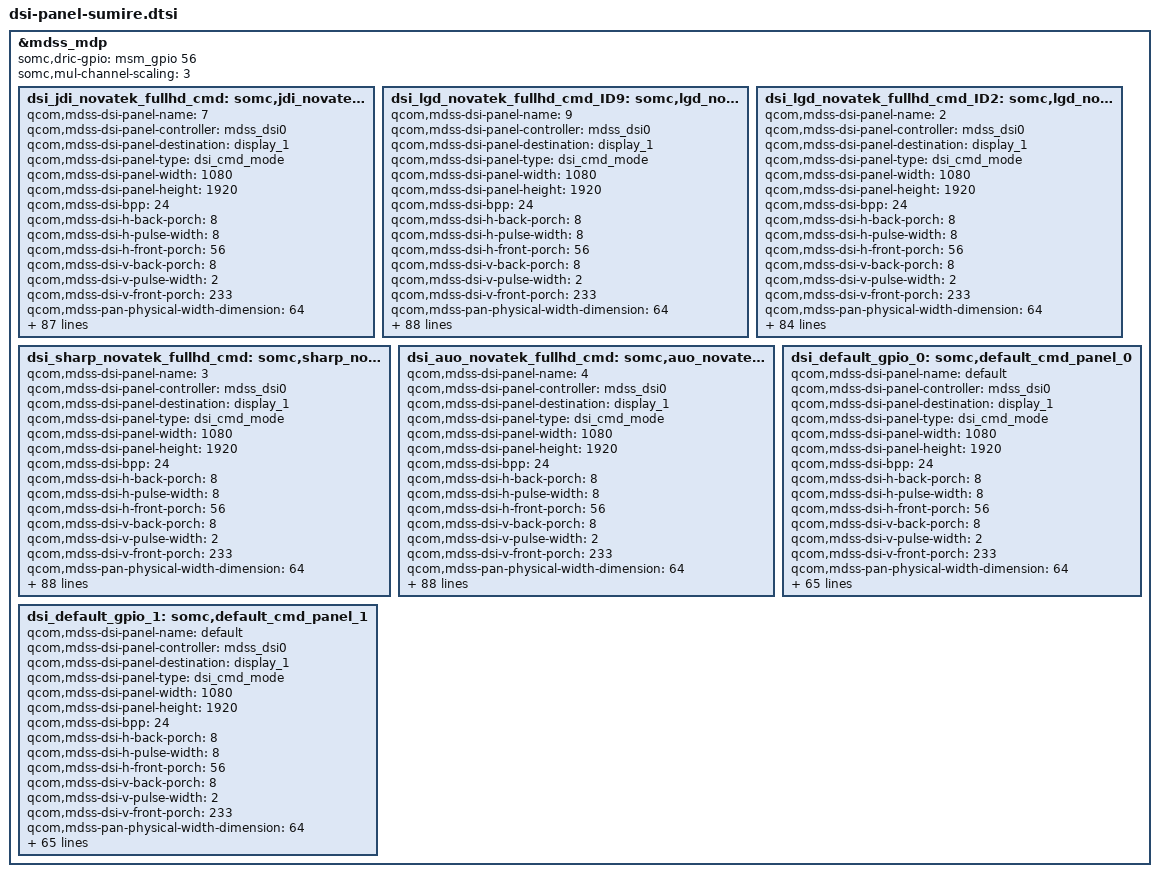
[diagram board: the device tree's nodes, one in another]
/* Copyright (c) 2013-2015, The Linux Foundation. All rights reserved.
 *
 * This program is free software; you can redistribute it and/or modify
 * it under the terms of the GNU General Public License version 2 and
 * only version 2 as published by the Free Software Foundation.
 *
 * This program is distributed in the hope that it will be useful,
 * but WITHOUT ANY WARRANTY; without even the implied warranty of
 * MERCHANTABILITY or FITNESS FOR A PARTICULAR PURPOSE.  See the
 * GNU General Public License for more details.
 */
/*
 * Copyright (C) 2015 Sony Mobile Communications Inc.
 *
 * This program is free software; you can redistribute it and/or modify
 * it under the terms of the GNU General Public License version 2, as
 * published by the Free Software Foundation.
 */

&mdss_mdp {
	somc,dric-gpio = <&msm_gpio 56 0>;
	somc,mul-channel-scaling = <3>;

	dsi_jdi_novatek_fullhd_cmd: somc,jdi_novatek_fullhd_cmd_panel {
		qcom,mdss-dsi-panel-name = "7";
		qcom,mdss-dsi-panel-controller = <&mdss_dsi0>;
		qcom,mdss-dsi-panel-destination = "display_1";
		qcom,mdss-dsi-panel-type = "dsi_cmd_mode";
		qcom,mdss-dsi-panel-width = <1080>;
		qcom,mdss-dsi-panel-height = <1920>;
		qcom,mdss-dsi-bpp = <24>;
		qcom,mdss-dsi-h-back-porch = <8>;
		qcom,mdss-dsi-h-pulse-width = <8>;
		qcom,mdss-dsi-h-front-porch = <56>;
		qcom,mdss-dsi-v-back-porch = <8>;
		qcom,mdss-dsi-v-pulse-width = <2>;
		qcom,mdss-dsi-v-front-porch = <233>;
		qcom,mdss-pan-physical-width-dimension = <64>;
		qcom,mdss-pan-physical-height-dimension = <114>;
		qcom,mdss-dsi-panel-framerate = <60>;
		qcom,mdss-dsi-virtual-channel-id = <0>;
		qcom,mdss-dsi-stream = <0>;
		qcom,mdss-dsi-h-sync-skew = <0>;
		qcom,mdss-dsi-h-left-border = <0>;
		qcom,mdss-dsi-h-right-border = <0>;
		qcom,mdss-dsi-v-top-border = <0>;
		qcom,mdss-dsi-v-bottom-border = <0>;
		qcom,mdss-dsi-underflow-color = <0x0>;
		qcom,mdss-dsi-border-color = <0>;
		qcom,mdss-dsi-h-sync-pulse = <1>;
		qcom,mdss-dsi-traffic-mode = "non_burst_sync_event";
		qcom,mdss-dsi-bllp-eof-power-mode;
		qcom,mdss-dsi-bllp-power-mode;
		qcom,mdss-dsi-dma-trigger = "trigger_sw";
		qcom,mdss-dsi-mdp-trigger = "none";
		somc,mdss-dsi-init-command = [23 01 00 00 00 00 02 FF 10
				05 01 00 00 14 00 01 01
				23 01 00 00 00 00 02 FB 01
				15 01 00 00 00 00 02 BB 10
				15 01 00 00 00 00 02 35 00
				39 01 00 00 00 00 03 44 03 00
				39 01 00 00 00 00 04 3B 03 08 08
				23 01 00 00 00 00 02 FF E0
				23 01 00 00 00 00 02 B5 86
				23 01 00 00 00 00 02 B6 77
				23 01 00 00 00 00 02 B8 AD
				23 01 00 00 00 00 02 FB 01
				23 01 00 00 00 00 02 FF 24
				23 01 00 00 00 00 02 FB 01
				23 01 00 00 00 00 02 92 8E
				23 01 00 00 00 00 02 FF 10
				23 01 00 00 01 00 02 FB 01
				05 01 00 00 00 00 01 29];
		qcom,mdss-dsi-on-command = [05 01 00 00 0A 00 01 11];
		qcom,mdss-dsi-off-command = [05 01 00 00 14 00 01 28
				05 01 00 00 50 00 01 10];
		qcom,mdss-dsi-on-command-state = "dsi_lp_mode";
		qcom,mdss-dsi-off-command-state = "dsi_hs_mode";
		qcom,mdss-dsi-te-pin-select = <1>;
		qcom,mdss-dsi-wr-mem-start = <0x2c>;
		qcom,mdss-dsi-wr-mem-continue = <0x3c>;
		qcom,mdss-dsi-te-dcs-command = <1>;
		qcom,mdss-dsi-te-check-enable;
		qcom,mdss-dsi-te-using-te-pin;
		qcom,mdss-dsi-lane-0-state;
		qcom,mdss-dsi-lane-1-state;
		qcom,mdss-dsi-lane-2-state;
		qcom,mdss-dsi-lane-3-state;
		qcom,mdss-dsi-panel-timings = [E6 38 26 00 68 66 32 3C 2C 03 04 00];
		qcom,mdss-dsi-t-clk-post = <0x21>;
		qcom,mdss-dsi-t-clk-pre = <0x2B>;
		qcom,mdss-dsi-tx-eot-append;
		qcom,mdss-dsi-lp11-init;
		qcom,mdss-dsi-bl-min-level = <1>;
		qcom,mdss-dsi-bl-max-level = <4095>;
		qcom,mdss-brightness-max-level = <4095>;
		qcom,mdss-dsi-bl-pmic-control-type = "bl_ctrl_wled";
		qcom,qpnp-lab-limit-maximum-current = <200>;
		qcom,qpnp-ibb-limit-maximum-current = <800>;

		somc,mdss-dsi-disp-on-in-hs = <0>;
		somc,mdss-dsi-wait-time-before-on-cmd = <0>;
		somc,platform-regulator-settings = [03 03 03 00 20 00 01];
		somc,mdss-dsi-lane-config = [02 00 EF 00 20 00 00 01 FF
				02 00 EF 00 40 00 00 01 FF
				02 00 EF 40 20 00 00 01 FF
				02 00 EF 40 00 00 00 01 FF
				00 00 45 80 00 00 00 01 97];
		somc,pw-on-rst-seq = <0 20>, <1 15>;
		somc,disp-en-off-post = <70>;
		somc,pw-off-rst-seq = <0 0>;
		somc,pw-down-period = <100>;
		somc,lab-output-voltage = <5400000>;
		somc,ibb-output-voltage = <5400000>;
		somc,lcd-id = <1>;
		somc,lcd-id-adc = <353000 414000>;
		somc,mdss-dsi-master;

		somc,change-fps-enable;
		somc,change-fps-command = [15 01 00 00 00 00 02 FF 24
				15 01 00 00 00 00 02 92 8E
				15 01 00 00 00 00 02 FF 10
				39 01 00 00 00 00 03 44 03 00];
		somc,display-clock = <16660000>;
		somc,driver-ic-vbp = <8>;
		somc,driver-ic-vfp = <8>;
		somc,change-fps-rtn-adj;
		somc,change-fps-rtn-pos = <1 1>;
		somc,fps-threshold = <47400>;
		somc,te-c-mode-60fps = <0x03 0x00>;
		somc,te-c-mode-45fps = <0x04 0xFF>;
		somc,te-c-mode-pos = <3 1>;

		somc,mdss-dsi-lock-command = [15 01 00 00 00 00 02 FF 10
				15 01 00 00 00 00 02 FB 01
				15 01 00 00 00 00 02 F0 55
				15 01 00 00 00 00 02 F1 AA
				15 01 00 00 01 00 02 F2 66];

		somc,mdss-dsi-unlock-command = [15 01 00 00 00 00 02 FF 10
				15 01 00 00 00 00 02 FB 01
				15 01 00 00 00 00 02 F0 AA
				15 01 00 00 00 00 02 F1 55
				15 01 00 00 01 00 02 F2 99];

		somc,mdss-dsi-pcc-enable;
		somc,mdss-dsi-uv-command = [06 01 00 00 00 00 01 DA
			06 01 00 00 00 00 01 DB];
		somc,mdss-dsi-uv-param-type = <4>;
		somc,mdss-dsi-pcc-table-size = <225>;
		somc,mdss-dsi-pcc-table = <
			0x00 0x01 0x38 0x3B 0x38 0x3B 0x5180 0x7000 0x8000
			0x00 0x02 0x34 0x37 0x38 0x3B 0x5500 0x7000 0x8000
			0x00 0x03 0x30 0x33 0x38 0x3B 0x5880 0x6F80 0x8000
			0x00 0x04 0x2C 0x2F 0x38 0x3B 0x5D00 0x6F00 0x8000
			0x00 0x05 0x28 0x2B 0x38 0x3B 0x6080 0x6E80 0x8000
			0x00 0x06 0x24 0x27 0x38 0x3B 0x6500 0x6E80 0x8000
			0x00 0x07 0x20 0x23 0x38 0x3B 0x6880 0x6E00 0x8000
			0x00 0x08 0x1C 0x1F 0x38 0x3B 0x6B80 0x6D80 0x8000
			0x00 0x09 0x18 0x1B 0x38 0x3B 0x6F00 0x6D80 0x8000
			0x00 0x0A 0x14 0x17 0x38 0x3B 0x7400 0x6D00 0x8000
			0x00 0x0B 0x10 0x13 0x38 0x3B 0x7B80 0x6D00 0x8000
			0x00 0x0C 0x0C 0x0F 0x38 0x3B 0x8000 0x6C00 0x8000
			0x00 0x0D 0x08 0x0B 0x38 0x3B 0x8000 0x6680 0x7900
			0x00 0x0E 0x04 0x07 0x38 0x3B 0x8000 0x5F80 0x7200
			0x00 0x0F 0x00 0x03 0x38 0x3B 0x8000 0x5780 0x6980
			0x00 0x10 0x38 0x3B 0x34 0x37 0x5600 0x7380 0x8000
			0x00 0x11 0x34 0x37 0x34 0x37 0x5980 0x7300 0x8000
			0x00 0x12 0x30 0x33 0x34 0x37 0x5D80 0x7300 0x8000
			0x00 0x13 0x2C 0x2F 0x34 0x37 0x6100 0x7280 0x8000
			0x00 0x14 0x28 0x2B 0x34 0x37 0x6500 0x7200 0x8000
			0x00 0x15 0x24 0x27 0x34 0x37 0x6880 0x7180 0x8000
			0x00 0x16 0x20 0x23 0x34 0x37 0x6B80 0x7100 0x8000
			0x00 0x17 0x1C 0x1F 0x34 0x37 0x6E80 0x7080 0x8000
			0x00 0x18 0x18 0x1B 0x34 0x37 0x7300 0x7080 0x8000
			0x00 0x19 0x14 0x17 0x34 0x37 0x7A00 0x7000 0x8000
			0x00 0x1A 0x10 0x13 0x34 0x37 0x7E80 0x6F80 0x8000
			0x00 0x1B 0x0C 0x0F 0x34 0x37 0x8000 0x6B00 0x7C80
			0x00 0x1C 0x08 0x0B 0x34 0x37 0x8000 0x6500 0x7500
			0x00 0x1D 0x04 0x07 0x34 0x37 0x8000 0x5D80 0x6D80
			0x00 0x1E 0x00 0x03 0x34 0x37 0x8000 0x5500 0x6500
			0x00 0x1F 0x38 0x3B 0x30 0x33 0x5A00 0x7700 0x8000
			0x00 0x20 0x34 0x37 0x30 0x33 0x5E00 0x7600 0x8000
			0x00 0x21 0x30 0x33 0x30 0x33 0x6100 0x7580 0x8000
			0x00 0x22 0x2C 0x2F 0x30 0x33 0x6500 0x7500 0x8000
			0x00 0x23 0x28 0x2B 0x30 0x33 0x6880 0x7480 0x8000
			0x00 0x24 0x24 0x27 0x30 0x33 0x6B80 0x7400 0x8000
			0x00 0x25 0x20 0x23 0x30 0x33 0x6E80 0x7380 0x8000
			0x00 0x26 0x1C 0x1F 0x30 0x33 0x7200 0x7380 0x8000
			0x00 0x27 0x18 0x1B 0x30 0x33 0x7880 0x7300 0x8000
			0x00 0x28 0x14 0x17 0x30 0x33 0x7D80 0x7300 0x8000
			0x00 0x29 0x10 0x13 0x30 0x33 0x8000 0x7080 0x7E80
			0x00 0x2A 0x0C 0x0F 0x30 0x33 0x8000 0x6A80 0x7780
			0x00 0x2B 0x08 0x0B 0x30 0x33 0x8000 0x6400 0x7180
			0x00 0x2C 0x04 0x07 0x30 0x33 0x8000 0x5C00 0x6980
			0x00 0x2D 0x00 0x03 0x30 0x33 0x8000 0x5280 0x6100
			0x00 0x2E 0x38 0x3B 0x2C 0x2F 0x5E00 0x7A80 0x8000
			0x00 0x2F 0x34 0x37 0x2C 0x2F 0x6180 0x7A00 0x8000
			0x00 0x30 0x30 0x33 0x2C 0x2F 0x6580 0x7900 0x8000
			0x00 0x31 0x2C 0x2F 0x2C 0x2F 0x6880 0x7880 0x8000
			0x00 0x32 0x28 0x2B 0x2C 0x2F 0x6B00 0x7800 0x8000
			0x00 0x33 0x24 0x27 0x2C 0x2F 0x6E00 0x7780 0x8000
			0x00 0x34 0x20 0x23 0x2C 0x2F 0x7180 0x7700 0x8000
			0x00 0x35 0x1C 0x1F 0x2C 0x2F 0x7780 0x7680 0x8000
			0x00 0x36 0x18 0x1B 0x2C 0x2F 0x7C80 0x7600 0x8000
			0x00 0x37 0x14 0x17 0x2C 0x2F 0x8000 0x7500 0x7F80
			0x00 0x38 0x10 0x13 0x2C 0x2F 0x8000 0x7000 0x7A80
			0x00 0x39 0x0C 0x0F 0x2C 0x2F 0x8000 0x6980 0x7400
			0x00 0x3A 0x08 0x0B 0x2C 0x2F 0x8000 0x6280 0x6D80
			0x00 0x3B 0x04 0x07 0x2C 0x2F 0x8000 0x5980 0x6600
			0x00 0x3C 0x00 0x03 0x2C 0x2F 0x8000 0x5000 0x5D80
			0x00 0x3D 0x38 0x3B 0x28 0x2B 0x6180 0x7E80 0x8000
			0x00 0x3E 0x34 0x37 0x28 0x2B 0x6580 0x7E00 0x8000
			0x00 0x3F 0x30 0x33 0x28 0x2B 0x6800 0x7D00 0x8000
			0x00 0x40 0x2C 0x2F 0x28 0x2B 0x6A80 0x7C80 0x8000
			0x00 0x41 0x28 0x2B 0x28 0x2B 0x6D80 0x7C00 0x8000
			0x00 0x42 0x24 0x27 0x28 0x2B 0x7100 0x7B00 0x8000
			0x00 0x43 0x20 0x23 0x28 0x2B 0x7600 0x7A80 0x8000
			0x00 0x44 0x1C 0x1F 0x28 0x2B 0x7B80 0x7900 0x8000
			0x00 0x45 0x18 0x1B 0x28 0x2B 0x7F80 0x7880 0x8000
			0x00 0x46 0x14 0x17 0x28 0x2B 0x8000 0x7480 0x7C80
			0x00 0x47 0x10 0x13 0x28 0x2B 0x8000 0x6F00 0x7680
			0x00 0x48 0x0C 0x0F 0x28 0x2B 0x8000 0x6880 0x7100
			0x00 0x49 0x08 0x0B 0x28 0x2B 0x8000 0x6080 0x6A80
			0x00 0x4A 0x04 0x07 0x28 0x2B 0x8000 0x5780 0x6300
			0x00 0x4B 0x00 0x03 0x28 0x2B 0x8000 0x4D00 0x5A00
			0x00 0x4C 0x38 0x3B 0x24 0x27 0x6300 0x8000 0x7E80
			0x00 0x4D 0x34 0x37 0x24 0x27 0x6780 0x8000 0x7F80
			0x00 0x4E 0x30 0x33 0x24 0x27 0x6A80 0x8000 0x8000
			0x00 0x4F 0x2C 0x2F 0x24 0x27 0x6D00 0x7F80 0x8000
			0x00 0x50 0x28 0x2B 0x24 0x27 0x7000 0x7F00 0x8000
			0x00 0x51 0x24 0x27 0x24 0x27 0x7400 0x7E80 0x8000
			0x00 0x52 0x20 0x23 0x24 0x27 0x7A80 0x7E00 0x8000
			0x00 0x53 0x1C 0x1F 0x24 0x27 0x7E00 0x7D00 0x8000
			0x00 0x54 0x18 0x1B 0x24 0x27 0x8000 0x7A00 0x7E00
			0x00 0x55 0x14 0x17 0x24 0x27 0x8000 0x7400 0x7880
			0x00 0x56 0x10 0x13 0x24 0x27 0x8000 0x6E80 0x7380
			0x00 0x57 0x0C 0x0F 0x24 0x27 0x8000 0x6780 0x6E00
			0x00 0x58 0x08 0x0B 0x24 0x27 0x8000 0x5F00 0x6700
			0x00 0x59 0x04 0x07 0x24 0x27 0x8000 0x5580 0x5F80
			0x00 0x5A 0x00 0x03 0x24 0x27 0x8000 0x4A00 0x5700
			0x00 0x5B 0x38 0x3B 0x20 0x23 0x6180 0x8000 0x7B00
			0x00 0x5C 0x34 0x37 0x20 0x23 0x6680 0x8000 0x7C80
			0x00 0x5D 0x30 0x33 0x20 0x23 0x6A00 0x8000 0x7D00
			0x00 0x5E 0x2C 0x2F 0x20 0x23 0x6D00 0x8000 0x7E00
			0x00 0x5F 0x28 0x2B 0x20 0x23 0x7100 0x8000 0x7E80
			0x00 0x60 0x24 0x27 0x20 0x23 0x7800 0x8000 0x7F00
			0x00 0x61 0x20 0x23 0x20 0x23 0x7D00 0x8000 0x8000
			0x00 0x62 0x1C 0x1F 0x20 0x23 0x8000 0x7F00 0x7F80
			0x00 0x63 0x18 0x1B 0x20 0x23 0x8000 0x7900 0x7B00
			0x00 0x64 0x14 0x17 0x20 0x23 0x8000 0x7380 0x7600
			0x00 0x65 0x10 0x13 0x20 0x23 0x8000 0x6D80 0x7100
			0x00 0x66 0x0C 0x0F 0x20 0x23 0x8000 0x6600 0x6B00
			0x00 0x67 0x08 0x0B 0x20 0x23 0x8000 0x5D80 0x6400
			0x00 0x68 0x04 0x07 0x20 0x23 0x8000 0x5400 0x5D00
			0x00 0x69 0x00 0x03 0x20 0x23 0x8000 0x4680 0x5480
			0x00 0x6A 0x38 0x3B 0x1C 0x1F 0x6080 0x8000 0x7780
			0x00 0x6B 0x34 0x37 0x1C 0x1F 0x6580 0x8000 0x7880
			0x00 0x6C 0x30 0x33 0x1C 0x1F 0x6900 0x8000 0x7980
			0x00 0x6D 0x2C 0x2F 0x1C 0x1F 0x6D00 0x8000 0x7A80
			0x00 0x6E 0x28 0x2B 0x1C 0x1F 0x7080 0x8000 0x7C00
			0x00 0x6F 0x24 0x27 0x1C 0x1F 0x7780 0x8000 0x7C80
			0x00 0x70 0x20 0x23 0x1C 0x1F 0x7D00 0x8000 0x7D00
			0x00 0x71 0x18 0x1B 0x1C 0x1F 0x8000 0x7900 0x7800
			0x00 0x72 0x14 0x17 0x1C 0x1F 0x8000 0x7300 0x7380
			0x00 0x73 0x10 0x13 0x1C 0x1F 0x8000 0x6D00 0x6E80
			0x00 0x74 0x0C 0x0F 0x1C 0x1F 0x8000 0x6500 0x6880
			0x00 0x75 0x08 0x0B 0x1C 0x1F 0x8000 0x5C00 0x6200
			0x00 0x76 0x04 0x07 0x1C 0x1F 0x8000 0x5180 0x5A00
			0x00 0x77 0x00 0x03 0x1C 0x1F 0x8000 0x4300 0x5200
			0x00 0x78 0x38 0x3B 0x18 0x1B 0x5F80 0x8000 0x7500
			0x00 0x79 0x34 0x37 0x18 0x1B 0x6480 0x8000 0x7600
			0x00 0x7A 0x30 0x33 0x18 0x1B 0x6900 0x8000 0x7680
			0x00 0x7B 0x2C 0x2F 0x18 0x1B 0x6C00 0x8000 0x7780
			0x00 0x7C 0x28 0x2B 0x18 0x1B 0x7000 0x8000 0x7880
			0x00 0x7D 0x24 0x27 0x18 0x1B 0x7600 0x8000 0x7900
			0x00 0x7E 0x20 0x23 0x18 0x1B 0x7C80 0x8000 0x7980
			0x00 0x7F 0x1C 0x1F 0x18 0x1B 0x8000 0x7F00 0x7980
			0x00 0x80 0x18 0x1B 0x18 0x1B 0x8000 0x7880 0x7580
			0x00 0x81 0x14 0x17 0x18 0x1B 0x8000 0x7300 0x7100
			0x00 0x82 0x10 0x13 0x18 0x1B 0x8000 0x6C00 0x6B80
			0x00 0x83 0x0C 0x0F 0x18 0x1B 0x8000 0x6400 0x6600
			0x00 0x84 0x08 0x0B 0x18 0x1B 0x8000 0x5A00 0x5F80
			0x00 0x85 0x04 0x07 0x18 0x1B 0x8000 0x4F00 0x5800
			0x00 0x86 0x00 0x03 0x18 0x1B 0x8000 0x3F80 0x4F80
			0x00 0x87 0x38 0x3B 0x14 0x17 0x5E00 0x8000 0x7200
			0x00 0x88 0x34 0x37 0x14 0x17 0x6300 0x8000 0x7300
			0x00 0x89 0x30 0x33 0x14 0x17 0x6800 0x8000 0x7400
			0x00 0x8A 0x2C 0x2F 0x14 0x17 0x6B80 0x8000 0x7500
			0x00 0x8B 0x28 0x2B 0x14 0x17 0x6F80 0x8000 0x7600
			0x00 0x8C 0x24 0x27 0x14 0x17 0x7500 0x8000 0x7680
			0x00 0x8D 0x20 0x23 0x14 0x17 0x7C80 0x8000 0x7780
			0x00 0x8E 0x1C 0x1F 0x14 0x17 0x8000 0x7F00 0x7780
			0x00 0x8F 0x18 0x1B 0x14 0x17 0x8000 0x7880 0x7380
			0x00 0x90 0x14 0x17 0x14 0x17 0x8000 0x7280 0x6F00
			0x00 0x91 0x10 0x13 0x14 0x17 0x8000 0x6B00 0x6980
			0x00 0x92 0x0C 0x0F 0x14 0x17 0x8000 0x6280 0x6380
			0x00 0x93 0x08 0x0B 0x14 0x17 0x8000 0x5880 0x5D80
			0x00 0x94 0x04 0x07 0x14 0x17 0x8000 0x4C00 0x5600
			0x00 0x95 0x00 0x03 0x14 0x17 0x8000 0x3B00 0x4D00
			0x00 0x96 0x38 0x3B 0x10 0x13 0x5D00 0x8000 0x7000
			0x00 0x97 0x34 0x37 0x10 0x13 0x6200 0x8000 0x7100
			0x00 0x98 0x30 0x33 0x10 0x13 0x6780 0x8000 0x7200
			0x00 0x99 0x2C 0x2F 0x10 0x13 0x6B00 0x8000 0x7300
			0x00 0x9A 0x28 0x2B 0x10 0x13 0x6F00 0x8000 0x7380
			0x00 0x9B 0x24 0x27 0x10 0x13 0x7500 0x8000 0x7480
			0x00 0x9C 0x20 0x23 0x10 0x13 0x7C80 0x8000 0x7580
			0x00 0x9D 0x1C 0x1F 0x10 0x13 0x8000 0x7F80 0x7580
			0x00 0x9E 0x18 0x1B 0x10 0x13 0x8000 0x7880 0x7180
			0x00 0x9F 0x14 0x17 0x10 0x13 0x8000 0x7200 0x6C00
			0x00 0xA0 0x10 0x13 0x10 0x13 0x8000 0x6A80 0x6780
			0x00 0xA1 0x0C 0x0F 0x10 0x13 0x8000 0x6180 0x6200
			0x00 0xA2 0x08 0x0B 0x10 0x13 0x8000 0x5680 0x5B00
			0x00 0xA3 0x04 0x07 0x10 0x13 0x8000 0x4980 0x5400
			0x00 0xA4 0x00 0x03 0x10 0x13 0x8000 0x3680 0x4A80
			0x00 0xA5 0x38 0x3B 0x0C 0x0F 0x5B00 0x8000 0x6D80
			0x00 0xA6 0x34 0x37 0x0C 0x0F 0x6080 0x8000 0x6E80
			0x00 0xA7 0x30 0x33 0x0C 0x0F 0x6680 0x8000 0x6F80
			0x00 0xA8 0x2C 0x2F 0x0C 0x0F 0x6A80 0x8000 0x7080
			0x00 0xA9 0x28 0x2B 0x0C 0x0F 0x6E80 0x8000 0x7180
			0x00 0xAA 0x24 0x27 0x0C 0x0F 0x7400 0x8000 0x7280
			0x00 0xAB 0x20 0x23 0x0C 0x0F 0x7C00 0x8000 0x7380
			0x00 0xAC 0x1C 0x1F 0x0C 0x0F 0x8000 0x7F80 0x7380
			0x00 0xAD 0x18 0x1B 0x0C 0x0F 0x8000 0x7800 0x6F80
			0x00 0xAE 0x14 0x17 0x0C 0x0F 0x8000 0x7180 0x6B00
			0x00 0xAF 0x10 0x13 0x0C 0x0F 0x8000 0x6980 0x6580
			0x00 0xB0 0x0C 0x0F 0x0C 0x0F 0x8000 0x6000 0x6000
			0x00 0xB1 0x08 0x0B 0x0C 0x0F 0x8000 0x5480 0x5980
			0x00 0xB2 0x04 0x07 0x0C 0x0F 0x8000 0x4680 0x5280
			0x00 0xB3 0x00 0x03 0x0C 0x0F 0x8000 0x3100 0x4880
			0x00 0xB4 0x38 0x3B 0x08 0x0B 0x5980 0x8000 0x6B00
			0x00 0xB5 0x34 0x37 0x08 0x0B 0x5F80 0x8000 0x6C00
			0x00 0xB6 0x30 0x33 0x08 0x0B 0x6580 0x8000 0x6D80
			0x00 0xB7 0x2C 0x2F 0x08 0x0B 0x6A00 0x8000 0x6E80
			0x00 0xB8 0x28 0x2B 0x08 0x0B 0x6E80 0x8000 0x6F80
			0x00 0xB9 0x24 0x27 0x08 0x0B 0x7380 0x8000 0x7080
			0x00 0xBA 0x20 0x23 0x08 0x0B 0x7C00 0x8000 0x7180
			0x00 0xBB 0x1C 0x1F 0x08 0x0B 0x8000 0x7F80 0x7180
			0x00 0xBC 0x18 0x1B 0x08 0x0B 0x8000 0x7800 0x6D80
			0x00 0xBD 0x14 0x17 0x08 0x0B 0x8000 0x7100 0x6900
			0x00 0xBE 0x10 0x13 0x08 0x0B 0x8000 0x6880 0x6400
			0x00 0xBF 0x0C 0x0F 0x08 0x0B 0x8000 0x5E80 0x5E80
			0x00 0xC0 0x08 0x0B 0x08 0x0B 0x8000 0x5380 0x5780
			0x00 0xC1 0x04 0x07 0x08 0x0B 0x8000 0x4400 0x5080
			0x00 0xC2 0x00 0x03 0x08 0x0B 0x8000 0x2B00 0x4680
			0x00 0xC3 0x38 0x3B 0x04 0x07 0x5800 0x8000 0x6900
			0x00 0xC4 0x34 0x37 0x04 0x07 0x5E80 0x8000 0x6A80
			0x00 0xC5 0x30 0x33 0x04 0x07 0x6480 0x8000 0x6B00
			0x00 0xC6 0x2C 0x2F 0x04 0x07 0x6980 0x8000 0x6D00
			0x00 0xC7 0x28 0x2B 0x04 0x07 0x6D80 0x8000 0x6E00
			0x00 0xC8 0x24 0x27 0x04 0x07 0x7300 0x8000 0x6F00
			0x00 0xC9 0x20 0x23 0x04 0x07 0x7B80 0x8000 0x6F80
			0x00 0xCA 0x1C 0x1F 0x04 0x07 0x8000 0x7F80 0x7000
			0x00 0xCB 0x18 0x1B 0x04 0x07 0x8000 0x7800 0x6B80
			0x00 0xCC 0x14 0x17 0x04 0x07 0x8000 0x7080 0x6780
			0x00 0xCD 0x10 0x13 0x04 0x07 0x8000 0x6800 0x6280
			0x00 0xCE 0x0C 0x0F 0x04 0x07 0x8000 0x5D80 0x5D00
			0x00 0xCF 0x08 0x0B 0x04 0x07 0x8000 0x5180 0x5680
			0x00 0xD0 0x04 0x07 0x04 0x07 0x8000 0x4080 0x4F00
			0x00 0xD1 0x00 0x03 0x04 0x07 0x8000 0x2800 0x4500
			0x00 0xD2 0x38 0x3B 0x00 0x03 0x5600 0x8000 0x6780
			0x00 0xD3 0x34 0x37 0x00 0x03 0x5D00 0x8000 0x6880
			0x00 0xD4 0x30 0x33 0x00 0x03 0x6300 0x8000 0x6A00
			0x00 0xD5 0x2C 0x2F 0x00 0x03 0x6900 0x8000 0x6B00
			0x00 0xD6 0x28 0x2B 0x00 0x03 0x6D00 0x8000 0x6B80
			0x00 0xD7 0x24 0x27 0x00 0x03 0x7280 0x8000 0x6D00
			0x00 0xD8 0x20 0x23 0x00 0x03 0x7B80 0x8000 0x6E00
			0x00 0xD9 0x1C 0x1F 0x00 0x03 0x8000 0x7F80 0x6E80
			0x00 0xDA 0x18 0x1B 0x00 0x03 0x8000 0x7780 0x6A80
			0x00 0xDB 0x14 0x17 0x00 0x03 0x8000 0x7000 0x6600
			0x00 0xDC 0x10 0x13 0x00 0x03 0x8000 0x6700 0x6100
			0x00 0xDD 0x0C 0x0F 0x00 0x03 0x8000 0x5C00 0x5B80
			0x00 0xDE 0x08 0x0B 0x00 0x03 0x8000 0x4F80 0x5480
			0x00 0xDF 0x04 0x07 0x00 0x03 0x8000 0x3D00 0x4D00
			0x00 0xE0 0x00 0x03 0x00 0x03 0x8000 0x2800 0x4380
			0xFF 0x00 0x00 0x3B 0x00 0x3B 0x8000 0x8000 0x8000>;
	};

	dsi_lgd_novatek_fullhd_cmd_ID9: somc,lgd_novatek_fullhd_cmd_panel_ID9 {
		qcom,mdss-dsi-panel-name = "9";
		qcom,mdss-dsi-panel-controller = <&mdss_dsi0>;
		qcom,mdss-dsi-panel-destination = "display_1";
		qcom,mdss-dsi-panel-type = "dsi_cmd_mode";
		qcom,mdss-dsi-panel-width = <1080>;
		qcom,mdss-dsi-panel-height = <1920>;
		qcom,mdss-dsi-bpp = <24>;
		qcom,mdss-dsi-h-back-porch = <8>;
		qcom,mdss-dsi-h-pulse-width = <8>;
		qcom,mdss-dsi-h-front-porch = <56>;
		qcom,mdss-dsi-v-back-porch = <8>;
		qcom,mdss-dsi-v-pulse-width = <2>;
		qcom,mdss-dsi-v-front-porch = <233>;
		qcom,mdss-pan-physical-width-dimension = <64>;
		qcom,mdss-pan-physical-height-dimension = <114>;
		qcom,mdss-dsi-panel-framerate = <60>;
		qcom,mdss-dsi-virtual-channel-id = <0>;
		qcom,mdss-dsi-stream = <0>;
		qcom,mdss-dsi-h-sync-skew = <0>;
		qcom,mdss-dsi-h-left-border = <0>;
		qcom,mdss-dsi-h-right-border = <0>;
		qcom,mdss-dsi-v-top-border = <0>;
		qcom,mdss-dsi-v-bottom-border = <0>;
		qcom,mdss-dsi-underflow-color = <0x0>;
		qcom,mdss-dsi-border-color = <0>;
		qcom,mdss-dsi-h-sync-pulse = <1>;
		qcom,mdss-dsi-traffic-mode = "non_burst_sync_event";
		qcom,mdss-dsi-bllp-eof-power-mode;
		qcom,mdss-dsi-bllp-power-mode;
		qcom,mdss-dsi-dma-trigger = "trigger_sw";
		qcom,mdss-dsi-mdp-trigger = "none";
		somc,mdss-dsi-init-command = [15 01 00 00 00 00 02 FF 20
				15 01 00 00 00 00 02 FB 01
				15 01 00 00 00 00 02 2D 94
				15 01 00 00 00 00 02 60 05
				15 01 00 00 00 00 02 FF E0
				15 01 00 00 00 00 02 FB 01
				15 01 00 00 00 00 02 B8 AD
				15 01 00 00 00 00 02 B5 86
				15 01 00 00 00 00 02 B6 77
				15 01 00 00 00 00 02 FF 24
				15 01 00 00 00 00 02 FB 01
				15 01 00 00 00 00 02 C4 24
				15 01 00 00 00 00 02 92 8E
				15 01 00 00 00 00 02 FF 10
				15 01 00 00 00 00 02 FB 01
				15 01 00 00 00 00 02 35 00
				39 01 00 00 00 00 03 44 03 00
				05 01 00 00 1E 00 01 11];
		qcom,mdss-dsi-on-command = [05 01 00 00 00 00 01 29];
		qcom,mdss-dsi-off-command = [05 01 00 00 14 00 01 28
				05 01 00 00 64 00 01 10];
		qcom,mdss-dsi-on-command-state = "dsi_lp_mode";
		qcom,mdss-dsi-off-command-state = "dsi_hs_mode";
		qcom,mdss-dsi-te-pin-select = <1>;
		qcom,mdss-dsi-wr-mem-start = <0x2c>;
		qcom,mdss-dsi-wr-mem-continue = <0x3c>;
		qcom,mdss-dsi-te-dcs-command = <1>;
		qcom,mdss-dsi-te-check-enable;
		qcom,mdss-dsi-te-using-te-pin;
		qcom,mdss-dsi-lane-0-state;
		qcom,mdss-dsi-lane-1-state;
		qcom,mdss-dsi-lane-2-state;
		qcom,mdss-dsi-lane-3-state;
		qcom,mdss-dsi-panel-timings = [E6 38 26 00 68 66 32 3C 2C 03 04 00];
		qcom,mdss-dsi-t-clk-post = <0x21>;
		qcom,mdss-dsi-t-clk-pre = <0x2B>;
		qcom,mdss-dsi-tx-eot-append;
		qcom,mdss-dsi-lp11-init;
		qcom,mdss-dsi-bl-min-level = <1>;
		qcom,mdss-dsi-bl-max-level = <4095>;
		qcom,mdss-brightness-max-level = <4095>;
		qcom,mdss-dsi-bl-pmic-control-type = "bl_ctrl_wled";
		qcom,qpnp-lab-limit-maximum-current = <200>;
		qcom,qpnp-ibb-limit-maximum-current = <800>;

		somc,mdss-dsi-disp-on-in-hs = <0>;
		somc,mdss-dsi-wait-time-before-on-cmd = <0>;
		somc,platform-regulator-settings = [03 03 03 00 20 00 01];
		somc,mdss-dsi-lane-config = [02 00 EF 00 20 00 00 01 FF
				02 00 EF 00 40 00 00 01 FF
				02 00 EF 40 20 00 00 01 FF
				02 00 EF 40 00 00 00 01 FF
				00 00 45 80 00 00 00 01 97];
		somc,disp-en-on-pre = <1>;
		somc,pw-on-rst-seq = <0 20>, <1 10>, <0 1>, <1 20>;
		somc,disp-en-off-post = <10>;
		somc,pw-off-rst-seq = <0 1>;
		somc,pw-down-period = <100>;
		somc,lab-output-voltage = <5700000>;
		somc,ibb-output-voltage = <5700000>;
		somc,lcd-id = <1>;
		somc,lcd-id-adc = <0 57000>;
		somc,mdss-dsi-master;

		somc,change-fps-enable;
		somc,change-fps-command = [15 01 00 00 00 00 02 FF 24
				15 01 00 00 00 00 02 92 8E
				15 01 00 00 00 00 02 FF 10
				39 01 00 00 00 00 03 44 03 00];
		somc,display-clock = <16660000>;
		somc,driver-ic-vbp = <4>;
		somc,driver-ic-vfp = <10>;
		somc,change-fps-rtn-adj;
		somc,change-fps-rtn-pos = <1 1>;
		somc,fps-threshold = <47400>;
		somc,te-c-mode-60fps = <0x03 0x00>;
		somc,te-c-mode-45fps = <0x04 0xFF>;
		somc,te-c-mode-pos = <3 1>;

		somc,mdss-dsi-lock-command = [15 01 00 00 00 00 02 FF 10
				15 01 00 00 00 00 02 FB 01
				15 01 00 00 00 00 02 F0 55
				15 01 00 00 00 00 02 F1 AA
				15 01 00 00 01 00 02 F2 66];

		somc,mdss-dsi-unlock-command = [15 01 00 00 00 00 02 FF 10
				15 01 00 00 00 00 02 FB 01
				15 01 00 00 00 00 02 F0 AA
				15 01 00 00 00 00 02 F1 55
				15 01 00 00 01 00 02 F2 99];

		somc,mdss-dsi-pcc-enable;
		somc,mdss-dsi-uv-command = [06 01 00 00 00 00 01 DA
			06 01 00 00 00 00 01 DB];
		somc,mdss-dsi-uv-param-type = <4>;
		somc,mdss-dsi-pcc-table-size = <225>;
		somc,mdss-dsi-pcc-table = <
			0x00 0x01 0x38 0x3B 0x38 0x3B 0x8000 0x8000 0x8000
			0x00 0x02 0x34 0x37 0x38 0x3B 0x8000 0x8000 0x8000
			0x00 0x03 0x30 0x33 0x38 0x3B 0x8000 0x8000 0x8000
			0x00 0x04 0x2C 0x2F 0x38 0x3B 0x8000 0x8000 0x8000
			0x00 0x05 0x28 0x2B 0x38 0x3B 0x8000 0x8000 0x8000
			0x00 0x06 0x24 0x27 0x38 0x3B 0x8000 0x8000 0x8000
			0x00 0x07 0x20 0x23 0x38 0x3B 0x8000 0x8000 0x8000
			0x00 0x08 0x1C 0x1F 0x38 0x3B 0x8000 0x8000 0x8000
			0x00 0x09 0x18 0x1B 0x38 0x3B 0x8000 0x8000 0x8000
			0x00 0x0A 0x14 0x17 0x38 0x3B 0x8000 0x8000 0x8000
			0x00 0x0B 0x10 0x13 0x38 0x3B 0x8000 0x8000 0x8000
			0x00 0x0C 0x0C 0x0F 0x38 0x3B 0x8000 0x8000 0x8000
			0x00 0x0D 0x08 0x0B 0x38 0x3B 0x8000 0x8000 0x8000
			0x00 0x0E 0x04 0x07 0x38 0x3B 0x8000 0x8000 0x8000
			0x00 0x0F 0x00 0x03 0x38 0x3B 0x8000 0x8000 0x8000
			0x00 0x10 0x38 0x3B 0x34 0x37 0x8000 0x8000 0x8000
			0x00 0x11 0x34 0x37 0x34 0x37 0x8000 0x8000 0x8000
			0x00 0x12 0x30 0x33 0x34 0x37 0x8000 0x8000 0x8000
			0x00 0x13 0x2C 0x2F 0x34 0x37 0x8000 0x8000 0x8000
			0x00 0x14 0x28 0x2B 0x34 0x37 0x8000 0x8000 0x8000
			0x00 0x15 0x24 0x27 0x34 0x37 0x8000 0x8000 0x8000
			0x00 0x16 0x20 0x23 0x34 0x37 0x8000 0x8000 0x8000
			0x00 0x17 0x1C 0x1F 0x34 0x37 0x8000 0x8000 0x8000
			0x00 0x18 0x18 0x1B 0x34 0x37 0x8000 0x8000 0x8000
			0x00 0x19 0x14 0x17 0x34 0x37 0x8000 0x8000 0x8000
			0x00 0x1A 0x10 0x13 0x34 0x37 0x8000 0x8000 0x8000
			0x00 0x1B 0x0C 0x0F 0x34 0x37 0x8000 0x8000 0x8000
			0x00 0x1C 0x08 0x0B 0x34 0x37 0x8000 0x8000 0x8000
			0x00 0x1D 0x04 0x07 0x34 0x37 0x8000 0x8000 0x8000
			0x00 0x1E 0x00 0x03 0x34 0x37 0x8000 0x8000 0x8000
			0x00 0x1F 0x38 0x3B 0x30 0x33 0x8000 0x8000 0x8000
			0x00 0x20 0x34 0x37 0x30 0x33 0x8000 0x8000 0x8000
			0x00 0x21 0x30 0x33 0x30 0x33 0x6B80 0x7280 0x8000
			0x00 0x22 0x2C 0x2F 0x30 0x33 0x6F80 0x7200 0x8000
			0x00 0x23 0x28 0x2B 0x30 0x33 0x7380 0x7180 0x8000
			0x00 0x24 0x24 0x27 0x30 0x33 0x7780 0x7100 0x8000
			0x00 0x25 0x20 0x23 0x30 0x33 0x7300 0x7180 0x8000
			0x00 0x26 0x1C 0x1F 0x30 0x33 0x7700 0x7100 0x8000
			0x00 0x27 0x18 0x1B 0x30 0x33 0x7B80 0x7080 0x8000
			0x00 0x28 0x14 0x17 0x30 0x33 0x7600 0x7180 0x8000
			0x00 0x29 0x10 0x13 0x30 0x33 0x7B00 0x7100 0x8000
			0x00 0x2A 0x0C 0x0F 0x30 0x33 0x7580 0x7180 0x8000
			0x00 0x2B 0x08 0x0B 0x30 0x33 0x7A00 0x7100 0x8000
			0x00 0x2C 0x04 0x07 0x30 0x33 0x8000 0x8000 0x8000
			0x00 0x2D 0x00 0x03 0x30 0x33 0x8000 0x8000 0x8000
			0x00 0x2E 0x38 0x3B 0x2C 0x2F 0x8000 0x8000 0x8000
			0x00 0x2F 0x34 0x37 0x2C 0x2F 0x8000 0x8000 0x8000
			0x00 0x30 0x30 0x33 0x2C 0x2F 0x6F80 0x7580 0x8000
			0x00 0x31 0x2C 0x2F 0x2C 0x2F 0x7300 0x7500 0x8000
			0x00 0x32 0x28 0x2B 0x2C 0x2F 0x7700 0x7480 0x8000
			0x00 0x33 0x24 0x27 0x2C 0x2F 0x7B00 0x7400 0x8000
			0x00 0x34 0x20 0x23 0x2C 0x2F 0x7600 0x7480 0x8000
			0x00 0x35 0x1C 0x1F 0x2C 0x2F 0x7580 0x7480 0x8000
			0x00 0x36 0x18 0x1B 0x2C 0x2F 0x7480 0x7480 0x8000
			0x00 0x37 0x14 0x17 0x2C 0x2F 0x7900 0x7400 0x8000
			0x00 0x38 0x10 0x13 0x2C 0x2F 0x7400 0x7500 0x8000
			0x00 0x39 0x0C 0x0F 0x2C 0x2F 0x7800 0x7400 0x8000
			0x00 0x3A 0x08 0x0B 0x2C 0x2F 0x7C80 0x7380 0x8000
			0x00 0x3B 0x04 0x07 0x2C 0x2F 0x8000 0x8000 0x8000
			0x00 0x3C 0x00 0x03 0x2C 0x2F 0x8000 0x8000 0x8000
			0x00 0x3D 0x38 0x3B 0x28 0x2B 0x8000 0x8000 0x8000
			0x00 0x3E 0x34 0x37 0x28 0x2B 0x8000 0x8000 0x8000
			0x00 0x3F 0x30 0x33 0x28 0x2B 0x7300 0x7880 0x8000
			0x00 0x40 0x2C 0x2F 0x28 0x2B 0x7600 0x7800 0x8000
			0x00 0x41 0x28 0x2B 0x28 0x2B 0x7A80 0x7780 0x8000
			0x00 0x42 0x24 0x27 0x28 0x2B 0x7500 0x7800 0x8000
			0x00 0x43 0x20 0x23 0x28 0x2B 0x7900 0x7780 0x8000
			0x00 0x44 0x1C 0x1F 0x28 0x2B 0x7880 0x7780 0x8000
			0x00 0x45 0x18 0x1B 0x28 0x2B 0x7C00 0x7700 0x8000
			0x00 0x46 0x14 0x17 0x28 0x2B 0x8000 0x7600 0x7F80
			0x00 0x47 0x10 0x13 0x28 0x2B 0x8000 0x7680 0x8000
			0x00 0x48 0x0C 0x0F 0x28 0x2B 0x7A80 0x7700 0x8000
			0x00 0x49 0x08 0x0B 0x28 0x2B 0x7F00 0x7680 0x8000
			0x00 0x4A 0x04 0x07 0x28 0x2B 0x8000 0x8000 0x8000
			0x00 0x4B 0x00 0x03 0x28 0x2B 0x8000 0x8000 0x8000
			0x00 0x4C 0x38 0x3B 0x24 0x27 0x8000 0x8000 0x8000
			0x00 0x4D 0x34 0x37 0x24 0x27 0x8000 0x8000 0x8000
			0x00 0x4E 0x30 0x33 0x24 0x27 0x7580 0x7B80 0x8000
			0x00 0x4F 0x2C 0x2F 0x24 0x27 0x7980 0x7B00 0x8000
			0x00 0x50 0x28 0x2B 0x24 0x27 0x7400 0x7B80 0x8000
			0x00 0x51 0x24 0x27 0x24 0x27 0x7800 0x7B00 0x8000
			0x00 0x52 0x20 0x23 0x24 0x27 0x7700 0x7B00 0x8000
			0x00 0x53 0x1C 0x1F 0x24 0x27 0x7B80 0x7A80 0x8000
			0x00 0x54 0x18 0x1B 0x24 0x27 0x7F00 0x7A00 0x8000
			0x00 0x55 0x14 0x17 0x24 0x27 0x8000 0x7580 0x7C00
			0x00 0x56 0x10 0x13 0x24 0x27 0x8000 0x7600 0x7D80
			0x00 0x57 0x0C 0x0F 0x24 0x27 0x7C80 0x7A00 0x8000
			0x00 0x58 0x08 0x0B 0x24 0x27 0x8000 0x7800 0x7F00
			0x00 0x59 0x04 0x07 0x24 0x27 0x8000 0x8000 0x8000
			0x00 0x5A 0x00 0x03 0x24 0x27 0x8000 0x8000 0x8000
			0x00 0x5B 0x38 0x3B 0x20 0x23 0x8000 0x8000 0x8000
			0x00 0x5C 0x34 0x37 0x20 0x23 0x8000 0x8000 0x8000
			0x00 0x5D 0x30 0x33 0x20 0x23 0x7900 0x7E80 0x8000
			0x00 0x5E 0x2C 0x2F 0x20 0x23 0x7380 0x7F80 0x8000
			0x00 0x5F 0x28 0x2B 0x20 0x23 0x7700 0x7E80 0x8000
			0x00 0x60 0x24 0x27 0x20 0x23 0x7600 0x7E80 0x8000
			0x00 0x61 0x20 0x23 0x20 0x23 0x7A00 0x7E00 0x8000
			0x00 0x62 0x1C 0x1F 0x20 0x23 0x7D80 0x7D80 0x8000
			0x00 0x63 0x18 0x1B 0x20 0x23 0x8000 0x7B00 0x7E80
			0x00 0x64 0x14 0x17 0x20 0x23 0x8000 0x7500 0x7980
			0x00 0x65 0x10 0x13 0x20 0x23 0x8000 0x7600 0x7A00
			0x00 0x66 0x0C 0x0F 0x20 0x23 0x7F00 0x7D00 0x8000
			0x00 0x67 0x08 0x0B 0x20 0x23 0x8000 0x7780 0x7B80
			0x00 0x68 0x04 0x07 0x20 0x23 0x8000 0x8000 0x8000
			0x00 0x69 0x00 0x03 0x20 0x23 0x8000 0x8000 0x8000
			0x00 0x6A 0x38 0x3B 0x1C 0x1F 0x8000 0x8000 0x8000
			0x00 0x6B 0x34 0x37 0x1C 0x1F 0x8000 0x8000 0x8000
			0x00 0x6C 0x30 0x33 0x1C 0x1F 0x7A80 0x8000 0x7F80
			0x00 0x6D 0x2C 0x2F 0x1C 0x1F 0x7400 0x8000 0x7E80
			0x00 0x6E 0x28 0x2B 0x1C 0x1F 0x7880 0x8000 0x7F00
			0x00 0x6F 0x24 0x27 0x1C 0x1F 0x7700 0x8000 0x7F00
			0x00 0x70 0x20 0x23 0x1C 0x1F 0x7C00 0x8000 0x7F80
			0x00 0x71 0x18 0x1B 0x1C 0x1F 0x8000 0x7B00 0x7B80
			0x00 0x72 0x14 0x17 0x1C 0x1F 0x8000 0x7500 0x7680
			0x00 0x73 0x10 0x13 0x1C 0x1F 0x8000 0x7580 0x7700
			0x00 0x74 0x0C 0x0F 0x1C 0x1F 0x8000 0x7E80 0x7F00
			0x00 0x75 0x08 0x0B 0x1C 0x1F 0x8000 0x7700 0x7800
			0x00 0x76 0x04 0x07 0x1C 0x1F 0x8000 0x8000 0x8000
			0x00 0x77 0x00 0x03 0x1C 0x1F 0x8000 0x8000 0x8000
			0x00 0x78 0x38 0x3B 0x18 0x1B 0x8000 0x8000 0x8000
			0x00 0x79 0x34 0x37 0x18 0x1B 0x8000 0x8000 0x8000
			0x00 0x7A 0x30 0x33 0x18 0x1B 0x7A00 0x8000 0x7C80
			0x00 0x7B 0x2C 0x2F 0x18 0x1B 0x7E80 0x8000 0x7D80
			0x00 0x7C 0x28 0x2B 0x18 0x1B 0x7780 0x8000 0x7C00
			0x00 0x7D 0x24 0x27 0x18 0x1B 0x7680 0x8000 0x7C00
			0x00 0x7E 0x20 0x23 0x18 0x1B 0x7B80 0x8000 0x7C80
			0x00 0x7F 0x1C 0x1F 0x18 0x1B 0x8000 0x8000 0x7D80
			0x00 0x80 0x18 0x1B 0x18 0x1B 0x8000 0x7B00 0x7980
			0x00 0x81 0x14 0x17 0x18 0x1B 0x8000 0x7C00 0x7A00
			0x00 0x82 0x10 0x13 0x18 0x1B 0x8000 0x7500 0x7480
			0x00 0x83 0x0C 0x0F 0x18 0x1B 0x8000 0x7E80 0x7C00
			0x00 0x84 0x08 0x0B 0x18 0x1B 0x8000 0x7680 0x7580
			0x00 0x85 0x04 0x07 0x18 0x1B 0x8000 0x8000 0x8000
			0x00 0x86 0x00 0x03 0x18 0x1B 0x8000 0x8000 0x8000
			0x00 0x87 0x38 0x3B 0x14 0x17 0x8000 0x8000 0x8000
			0x00 0x88 0x34 0x37 0x14 0x17 0x8000 0x8000 0x8000
			0x00 0x89 0x30 0x33 0x14 0x17 0x7980 0x8000 0x7A00
			0x00 0x8A 0x2C 0x2F 0x14 0x17 0x7E00 0x8000 0x7A80
			0x00 0x8B 0x28 0x2B 0x14 0x17 0x7700 0x8000 0x7980
			0x00 0x8C 0x24 0x27 0x14 0x17 0x7600 0x8000 0x7980
			0x00 0x8D 0x20 0x23 0x14 0x17 0x7B00 0x8000 0x7A00
			0x00 0x8E 0x1C 0x1F 0x14 0x17 0x8000 0x8000 0x7B00
			0x00 0x8F 0x18 0x1B 0x14 0x17 0x8000 0x7B00 0x7680
			0x00 0x90 0x14 0x17 0x14 0x17 0x8000 0x7C00 0x7780
			0x00 0x91 0x10 0x13 0x14 0x17 0x7C80 0x8000 0x7A80
			0x00 0x92 0x0C 0x0F 0x14 0x17 0x8000 0x7E00 0x7980
			0x00 0x93 0x08 0x0B 0x14 0x17 0x8000 0x7580 0x7300
			0x00 0x94 0x04 0x07 0x14 0x17 0x8000 0x8000 0x8000
			0x00 0x95 0x00 0x03 0x14 0x17 0x8000 0x8000 0x8000
			0x00 0x96 0x38 0x3B 0x10 0x13 0x8000 0x8000 0x8000
			0x00 0x97 0x34 0x37 0x10 0x13 0x8000 0x8000 0x8000
			0x00 0x98 0x30 0x33 0x10 0x13 0x7880 0x8000 0x7700
			0x00 0x99 0x2C 0x2F 0x10 0x13 0x7D80 0x8000 0x7800
			0x00 0x9A 0x28 0x2B 0x10 0x13 0x7680 0x8000 0x7680
			0x00 0x9B 0x24 0x27 0x10 0x13 0x7580 0x8000 0x7680
			0x00 0x9C 0x20 0x23 0x10 0x13 0x7B00 0x8000 0x7780
			0x00 0x9D 0x1C 0x1F 0x10 0x13 0x7F80 0x8000 0x7800
			0x00 0x9E 0x18 0x1B 0x10 0x13 0x8000 0x7B00 0x7480
			0x00 0x9F 0x14 0x17 0x10 0x13 0x8000 0x7C00 0x7500
			0x00 0xA0 0x10 0x13 0x10 0x13 0x7C80 0x8000 0x7800
			0x00 0xA1 0x0C 0x0F 0x10 0x13 0x8000 0x7E00 0x7700
			0x00 0xA2 0x08 0x0B 0x10 0x13 0x8000 0x7500 0x7080
			0x00 0xA3 0x04 0x07 0x10 0x13 0x8000 0x8000 0x8000
			0x00 0xA4 0x00 0x03 0x10 0x13 0x8000 0x8000 0x8000
			0x00 0xA5 0x38 0x3B 0x0C 0x0F 0x8000 0x8000 0x8000
			0x00 0xA6 0x34 0x37 0x0C 0x0F 0x8000 0x8000 0x8000
			0x00 0xA7 0x30 0x33 0x0C 0x0F 0x7800 0x8000 0x7500
			0x00 0xA8 0x2C 0x2F 0x0C 0x0F 0x7D00 0x8000 0x7580
			0x00 0xA9 0x28 0x2B 0x0C 0x0F 0x7600 0x8000 0x7480
			0x00 0xAA 0x24 0x27 0x0C 0x0F 0x7500 0x8000 0x7480
			0x00 0xAB 0x20 0x23 0x0C 0x0F 0x7A80 0x8000 0x7580
			0x00 0xAC 0x1C 0x1F 0x0C 0x0F 0x7F80 0x8000 0x7600
			0x00 0xAD 0x18 0x1B 0x0C 0x0F 0x7E80 0x8000 0x7600
			0x00 0xAE 0x14 0x17 0x0C 0x0F 0x7780 0x8000 0x7500
			0x00 0xAF 0x10 0x13 0x0C 0x0F 0x7C80 0x8000 0x7600
			0x00 0xB0 0x0C 0x0F 0x0C 0x0F 0x8000 0x7E00 0x7480
			0x00 0xB1 0x08 0x0B 0x0C 0x0F 0x8000 0x7480 0x6E80
			0x00 0xB2 0x04 0x07 0x0C 0x0F 0x8000 0x8000 0x8000
			0x00 0xB3 0x00 0x03 0x0C 0x0F 0x8000 0x8000 0x8000
			0x00 0xB4 0x38 0x3B 0x08 0x0B 0x8000 0x8000 0x8000
			0x00 0xB5 0x34 0x37 0x08 0x0B 0x8000 0x8000 0x8000
			0x00 0xB6 0x30 0x33 0x08 0x0B 0x7700 0x8000 0x7280
			0x00 0xB7 0x2C 0x2F 0x08 0x0B 0x7C80 0x8000 0x7380
			0x00 0xB8 0x28 0x2B 0x08 0x0B 0x8000 0x7E80 0x7380
			0x00 0xB9 0x24 0x27 0x08 0x0B 0x7B00 0x8000 0x7380
			0x00 0xBA 0x20 0x23 0x08 0x0B 0x8000 0x8000 0x7480
			0x00 0xBB 0x1C 0x1F 0x08 0x0B 0x7900 0x8000 0x7380
			0x00 0xBC 0x18 0x1B 0x08 0x0B 0x7E00 0x8000 0x7400
			0x00 0xBD 0x14 0x17 0x08 0x0B 0x7700 0x8000 0x7300
			0x00 0xBE 0x10 0x13 0x08 0x0B 0x7C80 0x8000 0x7400
			0x00 0xBF 0x0C 0x0F 0x08 0x0B 0x8000 0x7D80 0x7300
			0x00 0xC0 0x08 0x0B 0x08 0x0B 0x8000 0x7400 0x6C80
			0x00 0xC1 0x04 0x07 0x08 0x0B 0x8000 0x8000 0x8000
			0x00 0xC2 0x00 0x03 0x08 0x0B 0x8000 0x8000 0x8000
			0x00 0xC3 0x38 0x3B 0x04 0x07 0x8000 0x8000 0x8000
			0x00 0xC4 0x34 0x37 0x04 0x07 0x8000 0x8000 0x8000
			0x00 0xC5 0x30 0x33 0x04 0x07 0x8000 0x8000 0x8000
			0x00 0xC6 0x2C 0x2F 0x04 0x07 0x8000 0x8000 0x8000
			0x00 0xC7 0x28 0x2B 0x04 0x07 0x8000 0x8000 0x8000
			0x00 0xC8 0x24 0x27 0x04 0x07 0x8000 0x8000 0x8000
			0x00 0xC9 0x20 0x23 0x04 0x07 0x8000 0x8000 0x8000
			0x00 0xCA 0x1C 0x1F 0x04 0x07 0x8000 0x8000 0x8000
			0x00 0xCB 0x18 0x1B 0x04 0x07 0x8000 0x8000 0x8000
			0x00 0xCC 0x14 0x17 0x04 0x07 0x8000 0x8000 0x8000
			0x00 0xCD 0x10 0x13 0x04 0x07 0x8000 0x8000 0x8000
			0x00 0xCE 0x0C 0x0F 0x04 0x07 0x8000 0x8000 0x8000
			0x00 0xCF 0x08 0x0B 0x04 0x07 0x8000 0x8000 0x8000
			0x00 0xD0 0x04 0x07 0x04 0x07 0x8000 0x8000 0x8000
			0x00 0xD1 0x00 0x03 0x04 0x07 0x8000 0x8000 0x8000
			0x00 0xD2 0x38 0x3B 0x00 0x03 0x8000 0x8000 0x8000
			0x00 0xD3 0x34 0x37 0x00 0x03 0x8000 0x8000 0x8000
			0x00 0xD4 0x30 0x33 0x00 0x03 0x8000 0x8000 0x8000
			0x00 0xD5 0x2C 0x2F 0x00 0x03 0x8000 0x8000 0x8000
			0x00 0xD6 0x28 0x2B 0x00 0x03 0x8000 0x8000 0x8000
			0x00 0xD7 0x24 0x27 0x00 0x03 0x8000 0x8000 0x8000
			0x00 0xD8 0x20 0x23 0x00 0x03 0x8000 0x8000 0x8000
			0x00 0xD9 0x1C 0x1F 0x00 0x03 0x8000 0x8000 0x8000
			0x00 0xDA 0x18 0x1B 0x00 0x03 0x8000 0x8000 0x8000
			0x00 0xDB 0x14 0x17 0x00 0x03 0x8000 0x8000 0x8000
			0x00 0xDC 0x10 0x13 0x00 0x03 0x8000 0x8000 0x8000
			0x00 0xDD 0x0C 0x0F 0x00 0x03 0x8000 0x8000 0x8000
			0x00 0xDE 0x08 0x0B 0x00 0x03 0x8000 0x8000 0x8000
			0x00 0xDF 0x04 0x07 0x00 0x03 0x8000 0x8000 0x8000
			0x00 0xE0 0x00 0x03 0x00 0x03 0x8000 0x8000 0x8000
			0xFF 0x00 0x00 0x3B 0x00 0x3B 0x8000 0x8000 0x8000>;
	};

	dsi_lgd_novatek_fullhd_cmd_ID2: somc,lgd_novatek_fullhd_cmd_panel_ID2 {
		qcom,mdss-dsi-panel-name = "2";
		qcom,mdss-dsi-panel-controller = <&mdss_dsi0>;
		qcom,mdss-dsi-panel-destination = "display_1";
		qcom,mdss-dsi-panel-type = "dsi_cmd_mode";
		qcom,mdss-dsi-panel-width = <1080>;
		qcom,mdss-dsi-panel-height = <1920>;
		qcom,mdss-dsi-bpp = <24>;
		qcom,mdss-dsi-h-back-porch = <8>;
		qcom,mdss-dsi-h-pulse-width = <8>;
		qcom,mdss-dsi-h-front-porch = <56>;
		qcom,mdss-dsi-v-back-porch = <8>;
		qcom,mdss-dsi-v-pulse-width = <2>;
		qcom,mdss-dsi-v-front-porch = <233>;
		qcom,mdss-pan-physical-width-dimension = <64>;
		qcom,mdss-pan-physical-height-dimension = <114>;
		qcom,mdss-dsi-panel-framerate = <60>;
		qcom,mdss-dsi-virtual-channel-id = <0>;
		qcom,mdss-dsi-stream = <0>;
		qcom,mdss-dsi-h-sync-skew = <0>;
		qcom,mdss-dsi-h-left-border = <0>;
		qcom,mdss-dsi-h-right-border = <0>;
		qcom,mdss-dsi-v-top-border = <0>;
		qcom,mdss-dsi-v-bottom-border = <0>;
		qcom,mdss-dsi-underflow-color = <0x0>;
		qcom,mdss-dsi-border-color = <0>;
		qcom,mdss-dsi-h-sync-pulse = <1>;
		qcom,mdss-dsi-traffic-mode = "non_burst_sync_event";
		qcom,mdss-dsi-bllp-eof-power-mode;
		qcom,mdss-dsi-bllp-power-mode;
		qcom,mdss-dsi-dma-trigger = "trigger_sw";
		qcom,mdss-dsi-mdp-trigger = "none";
		somc,mdss-dsi-init-command = [15 01 00 00 00 00 02 FF 20
				15 01 00 00 00 00 02 FB 01
				15 01 00 00 00 00 02 2D 94
				15 01 00 00 00 00 02 FF E0
				15 01 00 00 00 00 02 FB 01
				15 01 00 00 00 00 02 B8 AD
				15 01 00 00 00 00 02 B5 86
				15 01 00 00 00 00 02 B6 77
				15 01 00 00 00 00 02 FF 24
				15 01 00 00 00 00 02 FB 01
				15 01 00 00 00 00 02 C4 24
				15 01 00 00 00 00 02 92 8E
				15 01 00 00 00 00 02 FF 10
				15 01 00 00 00 00 02 FB 01
				15 01 00 00 00 00 02 35 00
				39 01 00 00 00 00 03 44 03 00
				05 01 00 00 1E 00 01 11];
		qcom,mdss-dsi-on-command = [05 01 00 00 00 00 01 29];
		qcom,mdss-dsi-off-command = [05 01 00 00 14 00 01 28
				05 01 00 00 64 00 01 10];
		qcom,mdss-dsi-on-command-state = "dsi_lp_mode";
		qcom,mdss-dsi-off-command-state = "dsi_hs_mode";
		qcom,mdss-dsi-te-pin-select = <1>;
		qcom,mdss-dsi-wr-mem-start = <0x2c>;
		qcom,mdss-dsi-wr-mem-continue = <0x3c>;
		qcom,mdss-dsi-te-dcs-command = <1>;
		qcom,mdss-dsi-te-check-enable;
		qcom,mdss-dsi-te-using-te-pin;
		qcom,mdss-dsi-lane-0-state;
		qcom,mdss-dsi-lane-1-state;
		qcom,mdss-dsi-lane-2-state;
		qcom,mdss-dsi-lane-3-state;
		qcom,mdss-dsi-panel-timings = [E6 38 26 00 68 66 32 3C 2C 03 04 00];
		qcom,mdss-dsi-t-clk-post = <0x21>;
		qcom,mdss-dsi-t-clk-pre = <0x2B>;
		qcom,mdss-dsi-tx-eot-append;
		qcom,mdss-dsi-lp11-init;
		qcom,mdss-dsi-bl-min-level = <1>;
		qcom,mdss-dsi-bl-max-level = <4095>;
		qcom,mdss-brightness-max-level = <4095>;
		qcom,mdss-dsi-bl-pmic-control-type = "bl_ctrl_wled";
		qcom,qpnp-lab-limit-maximum-current = <200>;
		qcom,qpnp-ibb-limit-maximum-current = <800>;

		somc,mdss-dsi-disp-on-in-hs = <0>;
		somc,mdss-dsi-wait-time-before-on-cmd = <0>;
		somc,platform-regulator-settings = [03 03 03 00 20 00 01];
		somc,mdss-dsi-lane-config = [02 00 EF 00 20 00 00 01 FF
				02 00 EF 00 40 00 00 01 FF
				02 00 EF 40 20 00 00 01 FF
				02 00 EF 40 00 00 00 01 FF
				00 00 45 80 00 00 00 01 97];
		somc,disp-en-on-pre = <1>;
		somc,pw-on-rst-seq = <0 20>, <1 10>, <0 1>, <1 20>;
		somc,disp-en-off-post = <10>;
		somc,pw-off-rst-seq = <0 1>;
		somc,pw-down-period = <100>;
		somc,lab-output-voltage = <5700000>;
		somc,ibb-output-voltage = <5700000>;
		somc,lcd-id = <1>;
		somc,lcd-id-adc = <1420000 1594000>;
		somc,mdss-dsi-master;

		somc,change-fps-enable;
		somc,change-fps-command = [15 01 00 00 00 00 02 FF 24
				15 01 00 00 00 00 02 92 8E
				15 01 00 00 00 00 02 FF 10
				39 01 00 00 00 00 03 44 03 00];
		somc,display-clock = <16660000>;
		somc,driver-ic-vbp = <4>;
		somc,driver-ic-vfp = <10>;
		somc,change-fps-rtn-adj;
		somc,change-fps-rtn-pos = <1 1>;
		somc,fps-threshold = <47400>;
		somc,te-c-mode-60fps = <0x03 0x00>;
		somc,te-c-mode-45fps = <0x04 0xFF>;
		somc,te-c-mode-pos = <3 1>;

		somc,mdss-dsi-pcc-enable;
		somc,mdss-dsi-uv-command = [06 01 00 00 00 00 01 DA
			06 01 00 00 00 00 01 DB];
		somc,mdss-dsi-uv-param-type = <4>;
		somc,mdss-dsi-pcc-table-size = <225>;
		somc,mdss-dsi-pcc-table = <
			0x00 0x01 0x38 0x3B 0x38 0x3B 0x8000 0x8000 0x8000
			0x00 0x02 0x34 0x37 0x38 0x3B 0x8000 0x8000 0x8000
			0x00 0x03 0x30 0x33 0x38 0x3B 0x8000 0x8000 0x8000
			0x00 0x04 0x2C 0x2F 0x38 0x3B 0x8000 0x8000 0x8000
			0x00 0x05 0x28 0x2B 0x38 0x3B 0x8000 0x8000 0x8000
			0x00 0x06 0x24 0x27 0x38 0x3B 0x8000 0x8000 0x8000
			0x00 0x07 0x20 0x23 0x38 0x3B 0x8000 0x8000 0x8000
			0x00 0x08 0x1C 0x1F 0x38 0x3B 0x8000 0x8000 0x8000
			0x00 0x09 0x18 0x1B 0x38 0x3B 0x8000 0x8000 0x8000
			0x00 0x0A 0x14 0x17 0x38 0x3B 0x8000 0x8000 0x8000
			0x00 0x0B 0x10 0x13 0x38 0x3B 0x8000 0x8000 0x8000
			0x00 0x0C 0x0C 0x0F 0x38 0x3B 0x8000 0x8000 0x8000
			0x00 0x0D 0x08 0x0B 0x38 0x3B 0x8000 0x8000 0x8000
			0x00 0x0E 0x04 0x07 0x38 0x3B 0x8000 0x8000 0x8000
			0x00 0x0F 0x00 0x03 0x38 0x3B 0x8000 0x8000 0x8000
			0x00 0x10 0x38 0x3B 0x34 0x37 0x8000 0x8000 0x8000
			0x00 0x11 0x34 0x37 0x34 0x37 0x8000 0x8000 0x8000
			0x00 0x12 0x30 0x33 0x34 0x37 0x8000 0x8000 0x8000
			0x00 0x13 0x2C 0x2F 0x34 0x37 0x8000 0x8000 0x8000
			0x00 0x14 0x28 0x2B 0x34 0x37 0x8000 0x8000 0x8000
			0x00 0x15 0x24 0x27 0x34 0x37 0x8000 0x8000 0x8000
			0x00 0x16 0x20 0x23 0x34 0x37 0x8000 0x8000 0x8000
			0x00 0x17 0x1C 0x1F 0x34 0x37 0x8000 0x8000 0x8000
			0x00 0x18 0x18 0x1B 0x34 0x37 0x8000 0x8000 0x8000
			0x00 0x19 0x14 0x17 0x34 0x37 0x8000 0x8000 0x8000
			0x00 0x1A 0x10 0x13 0x34 0x37 0x8000 0x8000 0x8000
			0x00 0x1B 0x0C 0x0F 0x34 0x37 0x8000 0x8000 0x8000
			0x00 0x1C 0x08 0x0B 0x34 0x37 0x8000 0x8000 0x8000
			0x00 0x1D 0x04 0x07 0x34 0x37 0x8000 0x8000 0x8000
			0x00 0x1E 0x00 0x03 0x34 0x37 0x8000 0x8000 0x8000
			0x00 0x1F 0x38 0x3B 0x30 0x33 0x8000 0x8000 0x8000
			0x00 0x20 0x34 0x37 0x30 0x33 0x8000 0x8000 0x8000
			0x00 0x21 0x30 0x33 0x30 0x33 0x6B80 0x7280 0x8000
			0x00 0x22 0x2C 0x2F 0x30 0x33 0x6F80 0x7200 0x8000
			0x00 0x23 0x28 0x2B 0x30 0x33 0x7380 0x7180 0x8000
			0x00 0x24 0x24 0x27 0x30 0x33 0x7780 0x7100 0x8000
			0x00 0x25 0x20 0x23 0x30 0x33 0x7300 0x7180 0x8000
			0x00 0x26 0x1C 0x1F 0x30 0x33 0x7700 0x7100 0x8000
			0x00 0x27 0x18 0x1B 0x30 0x33 0x7B80 0x7080 0x8000
			0x00 0x28 0x14 0x17 0x30 0x33 0x7600 0x7180 0x8000
			0x00 0x29 0x10 0x13 0x30 0x33 0x7B00 0x7100 0x8000
			0x00 0x2A 0x0C 0x0F 0x30 0x33 0x7580 0x7180 0x8000
			0x00 0x2B 0x08 0x0B 0x30 0x33 0x7A00 0x7100 0x8000
			0x00 0x2C 0x04 0x07 0x30 0x33 0x8000 0x8000 0x8000
			0x00 0x2D 0x00 0x03 0x30 0x33 0x8000 0x8000 0x8000
			0x00 0x2E 0x38 0x3B 0x2C 0x2F 0x8000 0x8000 0x8000
			0x00 0x2F 0x34 0x37 0x2C 0x2F 0x8000 0x8000 0x8000
			0x00 0x30 0x30 0x33 0x2C 0x2F 0x6F80 0x7580 0x8000
			0x00 0x31 0x2C 0x2F 0x2C 0x2F 0x7300 0x7500 0x8000
			0x00 0x32 0x28 0x2B 0x2C 0x2F 0x7700 0x7480 0x8000
			0x00 0x33 0x24 0x27 0x2C 0x2F 0x7B00 0x7400 0x8000
			0x00 0x34 0x20 0x23 0x2C 0x2F 0x7600 0x7480 0x8000
			0x00 0x35 0x1C 0x1F 0x2C 0x2F 0x7580 0x7480 0x8000
			0x00 0x36 0x18 0x1B 0x2C 0x2F 0x7480 0x7480 0x8000
			0x00 0x37 0x14 0x17 0x2C 0x2F 0x7900 0x7400 0x8000
			0x00 0x38 0x10 0x13 0x2C 0x2F 0x7400 0x7500 0x8000
			0x00 0x39 0x0C 0x0F 0x2C 0x2F 0x7800 0x7400 0x8000
			0x00 0x3A 0x08 0x0B 0x2C 0x2F 0x7C80 0x7380 0x8000
			0x00 0x3B 0x04 0x07 0x2C 0x2F 0x8000 0x8000 0x8000
			0x00 0x3C 0x00 0x03 0x2C 0x2F 0x8000 0x8000 0x8000
			0x00 0x3D 0x38 0x3B 0x28 0x2B 0x8000 0x8000 0x8000
			0x00 0x3E 0x34 0x37 0x28 0x2B 0x8000 0x8000 0x8000
			0x00 0x3F 0x30 0x33 0x28 0x2B 0x7300 0x7880 0x8000
			0x00 0x40 0x2C 0x2F 0x28 0x2B 0x7600 0x7800 0x8000
			0x00 0x41 0x28 0x2B 0x28 0x2B 0x7A80 0x7780 0x8000
			0x00 0x42 0x24 0x27 0x28 0x2B 0x7500 0x7800 0x8000
			0x00 0x43 0x20 0x23 0x28 0x2B 0x7900 0x7780 0x8000
			0x00 0x44 0x1C 0x1F 0x28 0x2B 0x7880 0x7780 0x8000
			0x00 0x45 0x18 0x1B 0x28 0x2B 0x7C00 0x7700 0x8000
			0x00 0x46 0x14 0x17 0x28 0x2B 0x8000 0x7600 0x7F80
			0x00 0x47 0x10 0x13 0x28 0x2B 0x8000 0x7680 0x8000
			0x00 0x48 0x0C 0x0F 0x28 0x2B 0x7A80 0x7700 0x8000
			0x00 0x49 0x08 0x0B 0x28 0x2B 0x7F00 0x7680 0x8000
			0x00 0x4A 0x04 0x07 0x28 0x2B 0x8000 0x8000 0x8000
			0x00 0x4B 0x00 0x03 0x28 0x2B 0x8000 0x8000 0x8000
			0x00 0x4C 0x38 0x3B 0x24 0x27 0x8000 0x8000 0x8000
			0x00 0x4D 0x34 0x37 0x24 0x27 0x8000 0x8000 0x8000
			0x00 0x4E 0x30 0x33 0x24 0x27 0x7580 0x7B80 0x8000
			0x00 0x4F 0x2C 0x2F 0x24 0x27 0x7980 0x7B00 0x8000
			0x00 0x50 0x28 0x2B 0x24 0x27 0x7400 0x7B80 0x8000
			0x00 0x51 0x24 0x27 0x24 0x27 0x7800 0x7B00 0x8000
			0x00 0x52 0x20 0x23 0x24 0x27 0x7700 0x7B00 0x8000
			0x00 0x53 0x1C 0x1F 0x24 0x27 0x7B80 0x7A80 0x8000
			0x00 0x54 0x18 0x1B 0x24 0x27 0x7F00 0x7A00 0x8000
			0x00 0x55 0x14 0x17 0x24 0x27 0x8000 0x7580 0x7C00
			0x00 0x56 0x10 0x13 0x24 0x27 0x8000 0x7600 0x7D80
			0x00 0x57 0x0C 0x0F 0x24 0x27 0x7C80 0x7A00 0x8000
			0x00 0x58 0x08 0x0B 0x24 0x27 0x8000 0x7800 0x7F00
			0x00 0x59 0x04 0x07 0x24 0x27 0x8000 0x8000 0x8000
			0x00 0x5A 0x00 0x03 0x24 0x27 0x8000 0x8000 0x8000
			0x00 0x5B 0x38 0x3B 0x20 0x23 0x8000 0x8000 0x8000
			0x00 0x5C 0x34 0x37 0x20 0x23 0x8000 0x8000 0x8000
			0x00 0x5D 0x30 0x33 0x20 0x23 0x7900 0x7E80 0x8000
			0x00 0x5E 0x2C 0x2F 0x20 0x23 0x7380 0x7F80 0x8000
			0x00 0x5F 0x28 0x2B 0x20 0x23 0x7700 0x7E80 0x8000
			0x00 0x60 0x24 0x27 0x20 0x23 0x7600 0x7E80 0x8000
			0x00 0x61 0x20 0x23 0x20 0x23 0x7A00 0x7E00 0x8000
			0x00 0x62 0x1C 0x1F 0x20 0x23 0x7D80 0x7D80 0x8000
			0x00 0x63 0x18 0x1B 0x20 0x23 0x8000 0x7B00 0x7E80
			0x00 0x64 0x14 0x17 0x20 0x23 0x8000 0x7500 0x7980
			0x00 0x65 0x10 0x13 0x20 0x23 0x8000 0x7600 0x7A00
			0x00 0x66 0x0C 0x0F 0x20 0x23 0x7F00 0x7D00 0x8000
			0x00 0x67 0x08 0x0B 0x20 0x23 0x8000 0x7780 0x7B80
			0x00 0x68 0x04 0x07 0x20 0x23 0x8000 0x8000 0x8000
			0x00 0x69 0x00 0x03 0x20 0x23 0x8000 0x8000 0x8000
			0x00 0x6A 0x38 0x3B 0x1C 0x1F 0x8000 0x8000 0x8000
			0x00 0x6B 0x34 0x37 0x1C 0x1F 0x8000 0x8000 0x8000
			0x00 0x6C 0x30 0x33 0x1C 0x1F 0x7A80 0x8000 0x7F80
			0x00 0x6D 0x2C 0x2F 0x1C 0x1F 0x7400 0x8000 0x7E80
			0x00 0x6E 0x28 0x2B 0x1C 0x1F 0x7880 0x8000 0x7F00
			0x00 0x6F 0x24 0x27 0x1C 0x1F 0x7700 0x8000 0x7F00
			0x00 0x70 0x20 0x23 0x1C 0x1F 0x7C00 0x8000 0x7F80
			0x00 0x71 0x18 0x1B 0x1C 0x1F 0x8000 0x7B00 0x7B80
			0x00 0x72 0x14 0x17 0x1C 0x1F 0x8000 0x7500 0x7680
			0x00 0x73 0x10 0x13 0x1C 0x1F 0x8000 0x7580 0x7700
			0x00 0x74 0x0C 0x0F 0x1C 0x1F 0x8000 0x7E80 0x7F00
			0x00 0x75 0x08 0x0B 0x1C 0x1F 0x8000 0x7700 0x7800
			0x00 0x76 0x04 0x07 0x1C 0x1F 0x8000 0x8000 0x8000
			0x00 0x77 0x00 0x03 0x1C 0x1F 0x8000 0x8000 0x8000
			0x00 0x78 0x38 0x3B 0x18 0x1B 0x8000 0x8000 0x8000
			0x00 0x79 0x34 0x37 0x18 0x1B 0x8000 0x8000 0x8000
			0x00 0x7A 0x30 0x33 0x18 0x1B 0x7A00 0x8000 0x7C80
			0x00 0x7B 0x2C 0x2F 0x18 0x1B 0x7E80 0x8000 0x7D80
			0x00 0x7C 0x28 0x2B 0x18 0x1B 0x7780 0x8000 0x7C00
			0x00 0x7D 0x24 0x27 0x18 0x1B 0x7680 0x8000 0x7C00
			0x00 0x7E 0x20 0x23 0x18 0x1B 0x7B80 0x8000 0x7C80
			0x00 0x7F 0x1C 0x1F 0x18 0x1B 0x8000 0x8000 0x7D80
			0x00 0x80 0x18 0x1B 0x18 0x1B 0x8000 0x7B00 0x7980
			0x00 0x81 0x14 0x17 0x18 0x1B 0x8000 0x7C00 0x7A00
			0x00 0x82 0x10 0x13 0x18 0x1B 0x8000 0x7500 0x7480
			0x00 0x83 0x0C 0x0F 0x18 0x1B 0x8000 0x7E80 0x7C00
			0x00 0x84 0x08 0x0B 0x18 0x1B 0x8000 0x7680 0x7580
			0x00 0x85 0x04 0x07 0x18 0x1B 0x8000 0x8000 0x8000
			0x00 0x86 0x00 0x03 0x18 0x1B 0x8000 0x8000 0x8000
			0x00 0x87 0x38 0x3B 0x14 0x17 0x8000 0x8000 0x8000
			0x00 0x88 0x34 0x37 0x14 0x17 0x8000 0x8000 0x8000
			0x00 0x89 0x30 0x33 0x14 0x17 0x7980 0x8000 0x7A00
			0x00 0x8A 0x2C 0x2F 0x14 0x17 0x7E00 0x8000 0x7A80
			0x00 0x8B 0x28 0x2B 0x14 0x17 0x7700 0x8000 0x7980
			0x00 0x8C 0x24 0x27 0x14 0x17 0x7600 0x8000 0x7980
			0x00 0x8D 0x20 0x23 0x14 0x17 0x7B00 0x8000 0x7A00
			0x00 0x8E 0x1C 0x1F 0x14 0x17 0x8000 0x8000 0x7B00
			0x00 0x8F 0x18 0x1B 0x14 0x17 0x8000 0x7B00 0x7680
			0x00 0x90 0x14 0x17 0x14 0x17 0x8000 0x7C00 0x7780
			0x00 0x91 0x10 0x13 0x14 0x17 0x7C80 0x8000 0x7A80
			0x00 0x92 0x0C 0x0F 0x14 0x17 0x8000 0x7E00 0x7980
			0x00 0x93 0x08 0x0B 0x14 0x17 0x8000 0x7580 0x7300
			0x00 0x94 0x04 0x07 0x14 0x17 0x8000 0x8000 0x8000
			0x00 0x95 0x00 0x03 0x14 0x17 0x8000 0x8000 0x8000
			0x00 0x96 0x38 0x3B 0x10 0x13 0x8000 0x8000 0x8000
			0x00 0x97 0x34 0x37 0x10 0x13 0x8000 0x8000 0x8000
			0x00 0x98 0x30 0x33 0x10 0x13 0x7880 0x8000 0x7700
			0x00 0x99 0x2C 0x2F 0x10 0x13 0x7D80 0x8000 0x7800
			0x00 0x9A 0x28 0x2B 0x10 0x13 0x7680 0x8000 0x7680
			0x00 0x9B 0x24 0x27 0x10 0x13 0x7580 0x8000 0x7680
			0x00 0x9C 0x20 0x23 0x10 0x13 0x7B00 0x8000 0x7780
			0x00 0x9D 0x1C 0x1F 0x10 0x13 0x7F80 0x8000 0x7800
			0x00 0x9E 0x18 0x1B 0x10 0x13 0x8000 0x7B00 0x7480
			0x00 0x9F 0x14 0x17 0x10 0x13 0x8000 0x7C00 0x7500
			0x00 0xA0 0x10 0x13 0x10 0x13 0x7C80 0x8000 0x7800
			0x00 0xA1 0x0C 0x0F 0x10 0x13 0x8000 0x7E00 0x7700
			0x00 0xA2 0x08 0x0B 0x10 0x13 0x8000 0x7500 0x7080
			0x00 0xA3 0x04 0x07 0x10 0x13 0x8000 0x8000 0x8000
			0x00 0xA4 0x00 0x03 0x10 0x13 0x8000 0x8000 0x8000
			0x00 0xA5 0x38 0x3B 0x0C 0x0F 0x8000 0x8000 0x8000
			0x00 0xA6 0x34 0x37 0x0C 0x0F 0x8000 0x8000 0x8000
			0x00 0xA7 0x30 0x33 0x0C 0x0F 0x7800 0x8000 0x7500
			0x00 0xA8 0x2C 0x2F 0x0C 0x0F 0x7D00 0x8000 0x7580
			0x00 0xA9 0x28 0x2B 0x0C 0x0F 0x7600 0x8000 0x7480
			0x00 0xAA 0x24 0x27 0x0C 0x0F 0x7500 0x8000 0x7480
			0x00 0xAB 0x20 0x23 0x0C 0x0F 0x7A80 0x8000 0x7580
			0x00 0xAC 0x1C 0x1F 0x0C 0x0F 0x7F80 0x8000 0x7600
			0x00 0xAD 0x18 0x1B 0x0C 0x0F 0x7E80 0x8000 0x7600
			0x00 0xAE 0x14 0x17 0x0C 0x0F 0x7780 0x8000 0x7500
			0x00 0xAF 0x10 0x13 0x0C 0x0F 0x7C80 0x8000 0x7600
			0x00 0xB0 0x0C 0x0F 0x0C 0x0F 0x8000 0x7E00 0x7480
			0x00 0xB1 0x08 0x0B 0x0C 0x0F 0x8000 0x7480 0x6E80
			0x00 0xB2 0x04 0x07 0x0C 0x0F 0x8000 0x8000 0x8000
			0x00 0xB3 0x00 0x03 0x0C 0x0F 0x8000 0x8000 0x8000
			0x00 0xB4 0x38 0x3B 0x08 0x0B 0x8000 0x8000 0x8000
			0x00 0xB5 0x34 0x37 0x08 0x0B 0x8000 0x8000 0x8000
			0x00 0xB6 0x30 0x33 0x08 0x0B 0x7700 0x8000 0x7280
			0x00 0xB7 0x2C 0x2F 0x08 0x0B 0x7C80 0x8000 0x7380
			0x00 0xB8 0x28 0x2B 0x08 0x0B 0x8000 0x7E80 0x7380
			0x00 0xB9 0x24 0x27 0x08 0x0B 0x7B00 0x8000 0x7380
			0x00 0xBA 0x20 0x23 0x08 0x0B 0x8000 0x8000 0x7480
			0x00 0xBB 0x1C 0x1F 0x08 0x0B 0x7900 0x8000 0x7380
			0x00 0xBC 0x18 0x1B 0x08 0x0B 0x7E00 0x8000 0x7400
			0x00 0xBD 0x14 0x17 0x08 0x0B 0x7700 0x8000 0x7300
			0x00 0xBE 0x10 0x13 0x08 0x0B 0x7C80 0x8000 0x7400
			0x00 0xBF 0x0C 0x0F 0x08 0x0B 0x8000 0x7D80 0x7300
			0x00 0xC0 0x08 0x0B 0x08 0x0B 0x8000 0x7400 0x6C80
			0x00 0xC1 0x04 0x07 0x08 0x0B 0x8000 0x8000 0x8000
			0x00 0xC2 0x00 0x03 0x08 0x0B 0x8000 0x8000 0x8000
			0x00 0xC3 0x38 0x3B 0x04 0x07 0x8000 0x8000 0x8000
			0x00 0xC4 0x34 0x37 0x04 0x07 0x8000 0x8000 0x8000
			0x00 0xC5 0x30 0x33 0x04 0x07 0x8000 0x8000 0x8000
			0x00 0xC6 0x2C 0x2F 0x04 0x07 0x8000 0x8000 0x8000
			0x00 0xC7 0x28 0x2B 0x04 0x07 0x8000 0x8000 0x8000
			0x00 0xC8 0x24 0x27 0x04 0x07 0x8000 0x8000 0x8000
			0x00 0xC9 0x20 0x23 0x04 0x07 0x8000 0x8000 0x8000
			0x00 0xCA 0x1C 0x1F 0x04 0x07 0x8000 0x8000 0x8000
			0x00 0xCB 0x18 0x1B 0x04 0x07 0x8000 0x8000 0x8000
			0x00 0xCC 0x14 0x17 0x04 0x07 0x8000 0x8000 0x8000
			0x00 0xCD 0x10 0x13 0x04 0x07 0x8000 0x8000 0x8000
			0x00 0xCE 0x0C 0x0F 0x04 0x07 0x8000 0x8000 0x8000
			0x00 0xCF 0x08 0x0B 0x04 0x07 0x8000 0x8000 0x8000
			0x00 0xD0 0x04 0x07 0x04 0x07 0x8000 0x8000 0x8000
			0x00 0xD1 0x00 0x03 0x04 0x07 0x8000 0x8000 0x8000
			0x00 0xD2 0x38 0x3B 0x00 0x03 0x8000 0x8000 0x8000
			0x00 0xD3 0x34 0x37 0x00 0x03 0x8000 0x8000 0x8000
			0x00 0xD4 0x30 0x33 0x00 0x03 0x8000 0x8000 0x8000
			0x00 0xD5 0x2C 0x2F 0x00 0x03 0x8000 0x8000 0x8000
			0x00 0xD6 0x28 0x2B 0x00 0x03 0x8000 0x8000 0x8000
			0x00 0xD7 0x24 0x27 0x00 0x03 0x8000 0x8000 0x8000
			0x00 0xD8 0x20 0x23 0x00 0x03 0x8000 0x8000 0x8000
			0x00 0xD9 0x1C 0x1F 0x00 0x03 0x8000 0x8000 0x8000
			0x00 0xDA 0x18 0x1B 0x00 0x03 0x8000 0x8000 0x8000
			0x00 0xDB 0x14 0x17 0x00 0x03 0x8000 0x8000 0x8000
			0x00 0xDC 0x10 0x13 0x00 0x03 0x8000 0x8000 0x8000
			0x00 0xDD 0x0C 0x0F 0x00 0x03 0x8000 0x8000 0x8000
			0x00 0xDE 0x08 0x0B 0x00 0x03 0x8000 0x8000 0x8000
			0x00 0xDF 0x04 0x07 0x00 0x03 0x8000 0x8000 0x8000
			0x00 0xE0 0x00 0x03 0x00 0x03 0x8000 0x8000 0x8000
			0xFF 0x00 0x00 0x3B 0x00 0x3B 0x8000 0x8000 0x8000>;
	};

	dsi_sharp_novatek_fullhd_cmd: somc,sharp_novatek_fullhd_cmd_panel {
		qcom,mdss-dsi-panel-name = "3";
		qcom,mdss-dsi-panel-controller = <&mdss_dsi0>;
		qcom,mdss-dsi-panel-destination = "display_1";
		qcom,mdss-dsi-panel-type = "dsi_cmd_mode";
		qcom,mdss-dsi-panel-width = <1080>;
		qcom,mdss-dsi-panel-height = <1920>;
		qcom,mdss-dsi-bpp = <24>;
		qcom,mdss-dsi-h-back-porch = <8>;
		qcom,mdss-dsi-h-pulse-width = <8>;
		qcom,mdss-dsi-h-front-porch = <56>;
		qcom,mdss-dsi-v-back-porch = <8>;
		qcom,mdss-dsi-v-pulse-width = <2>;
		qcom,mdss-dsi-v-front-porch = <233>;
		qcom,mdss-pan-physical-width-dimension = <64>;
		qcom,mdss-pan-physical-height-dimension = <114>;
		qcom,mdss-dsi-panel-framerate = <60>;
		qcom,mdss-dsi-virtual-channel-id = <0>;
		qcom,mdss-dsi-stream = <0>;
		qcom,mdss-dsi-h-sync-skew = <0>;
		qcom,mdss-dsi-h-left-border = <0>;
		qcom,mdss-dsi-h-right-border = <0>;
		qcom,mdss-dsi-v-top-border = <0>;
		qcom,mdss-dsi-v-bottom-border = <0>;
		qcom,mdss-dsi-underflow-color = <0x0>;
		qcom,mdss-dsi-border-color = <0>;
		qcom,mdss-dsi-h-sync-pulse = <1>;
		qcom,mdss-dsi-traffic-mode = "non_burst_sync_event";
		qcom,mdss-dsi-bllp-eof-power-mode;
		qcom,mdss-dsi-bllp-power-mode;
		qcom,mdss-dsi-dma-trigger = "trigger_sw";
		qcom,mdss-dsi-mdp-trigger = "none";
		somc,mdss-dsi-init-command = [15 01 00 00 00 00 02 BB 10
				15 01 00 00 00 00 02 FF 20
				15 01 00 00 00 00 02 FB 01
				15 01 00 00 00 00 02 75 00
				15 01 00 00 00 00 02 76 39
				15 01 00 00 00 00 02 77 00
				15 01 00 00 00 00 02 78 64
				15 01 00 00 00 00 02 79 00
				15 01 00 00 00 00 02 7A 9B
				15 01 00 00 00 00 02 7B 00
				15 01 00 00 00 00 02 7C BD
				15 01 00 00 00 00 02 7D 00
				15 01 00 00 00 00 02 7E DA
				15 01 00 00 00 00 02 7F 00
				15 01 00 00 00 00 02 80 F1
				15 01 00 00 00 00 02 81 01
				15 01 00 00 00 00 02 82 03
				15 01 00 00 00 00 02 83 01
				15 01 00 00 00 00 02 84 10
				15 01 00 00 00 00 02 85 01
				15 01 00 00 00 00 02 86 1F
				15 01 00 00 00 00 02 87 01
				15 01 00 00 00 00 02 88 4E
				15 01 00 00 00 00 02 89 01
				15 01 00 00 00 00 02 8A 72
				15 01 00 00 00 00 02 8B 01
				15 01 00 00 00 00 02 8C B0
				15 01 00 00 00 00 02 8D 01
				15 01 00 00 00 00 02 8E E0
				15 01 00 00 00 00 02 8F 02
				15 01 00 00 00 00 02 90 27
				15 01 00 00 00 00 02 91 02
				15 01 00 00 00 00 02 92 5A
				15 01 00 00 00 00 02 93 02
				15 01 00 00 00 00 02 94 5C
				15 01 00 00 00 00 02 95 02
				15 01 00 00 00 00 02 96 8C
				15 01 00 00 00 00 02 97 02
				15 01 00 00 00 00 02 98 B9
				15 01 00 00 00 00 02 99 02
				15 01 00 00 00 00 02 9A D9
				15 01 00 00 00 00 02 9B 03
				15 01 00 00 00 00 02 9C 0A
				15 01 00 00 00 00 02 9D 03
				15 01 00 00 00 00 02 9E 23
				15 01 00 00 00 00 02 9F 03
				15 01 00 00 00 00 02 A0 7E
				15 01 00 00 00 00 02 A2 03
				15 01 00 00 00 00 02 A3 A6
				15 01 00 00 00 00 02 A4 03
				15 01 00 00 00 00 02 A5 CA
				15 01 00 00 00 00 02 A6 03
				15 01 00 00 00 00 02 A7 D7
				15 01 00 00 00 00 02 A9 03
				15 01 00 00 00 00 02 AA DA
				15 01 00 00 00 00 02 AB 03
				15 01 00 00 00 00 02 AC DC
				15 01 00 00 00 00 02 AD 03
				15 01 00 00 00 00 02 AE DC
				15 01 00 00 00 00 02 AF 03
				15 01 00 00 00 00 02 B0 DC
				15 01 00 00 00 00 02 B1 03
				15 01 00 00 00 00 02 B2 DC
				15 01 00 00 00 00 02 B3 00
				15 01 00 00 00 00 02 B4 74
				15 01 00 00 00 00 02 B5 00
				15 01 00 00 00 00 02 B6 9E
				15 01 00 00 00 00 02 B7 00
				15 01 00 00 00 00 02 B8 D2
				15 01 00 00 00 00 02 B9 00
				15 01 00 00 00 00 02 BA F1
				15 01 00 00 00 00 02 BB 01
				15 01 00 00 00 00 02 BC 0B
				15 01 00 00 00 00 02 BD 01
				15 01 00 00 00 00 02 BE 20
				15 01 00 00 00 00 02 BF 01
				15 01 00 00 00 00 02 C0 2F
				15 01 00 00 00 00 02 C1 01
				15 01 00 00 00 00 02 C2 3B
				15 01 00 00 00 00 02 C3 01
				15 01 00 00 00 00 02 C4 48
				15 01 00 00 00 00 02 C5 01
				15 01 00 00 00 00 02 C6 6F
				15 01 00 00 00 00 02 C7 01
				15 01 00 00 00 00 02 C8 8C
				15 01 00 00 00 00 02 C9 01
				15 01 00 00 00 00 02 CA B9
				15 01 00 00 00 00 02 CB 01
				15 01 00 00 00 00 02 CC DB
				15 01 00 00 00 00 02 CD 02
				15 01 00 00 00 00 02 CE 15
				15 01 00 00 00 00 02 CF 02
				15 01 00 00 00 00 02 D0 48
				15 01 00 00 00 00 02 D1 02
				15 01 00 00 00 00 02 D2 49
				15 01 00 00 00 00 02 D3 02
				15 01 00 00 00 00 02 D4 79
				15 01 00 00 00 00 02 D5 02
				15 01 00 00 00 00 02 D6 BF
				15 01 00 00 00 00 02 D7 02
				15 01 00 00 00 00 02 D8 EE
				15 01 00 00 00 00 02 D9 03
				15 01 00 00 00 00 02 DA 21
				15 01 00 00 00 00 02 DB 03
				15 01 00 00 00 00 02 DC 39
				15 01 00 00 00 00 02 DD 03
				15 01 00 00 00 00 02 DE 94
				15 01 00 00 00 00 02 DF 03
				15 01 00 00 00 00 02 E0 BB
				15 01 00 00 00 00 02 E1 03
				15 01 00 00 00 00 02 E2 E2
				15 01 00 00 00 00 02 E3 03
				15 01 00 00 00 00 02 E4 EE
				15 01 00 00 00 00 02 E5 03
				15 01 00 00 00 00 02 E6 F2
				15 01 00 00 00 00 02 E7 03
				15 01 00 00 00 00 02 E8 F3
				15 01 00 00 00 00 02 E9 03
				15 01 00 00 00 00 02 EA F3
				15 01 00 00 00 00 02 EB 03
				15 01 00 00 00 00 02 EC F3
				15 01 00 00 00 00 02 ED 03
				15 01 00 00 00 00 02 EE F3
				15 01 00 00 00 00 02 EF 00
				15 01 00 00 00 00 02 F0 7C
				15 01 00 00 00 00 02 F1 00
				15 01 00 00 00 00 02 F2 8B
				15 01 00 00 00 00 02 F3 00
				15 01 00 00 00 00 02 F4 AB
				15 01 00 00 00 00 02 F5 00
				15 01 00 00 00 00 02 F6 C7
				15 01 00 00 00 00 02 F7 00
				15 01 00 00 00 00 02 F8 DE
				15 01 00 00 00 00 02 F9 00
				15 01 00 00 00 00 02 FA F0
				15 01 00 00 00 00 02 FF 21
				15 01 00 00 00 00 02 FB 01
				15 01 00 00 00 00 02 00 01
				15 01 00 00 00 00 02 01 01
				15 01 00 00 00 00 02 02 01
				15 01 00 00 00 00 02 03 0E
				15 01 00 00 00 00 02 04 01
				15 01 00 00 00 00 02 05 1C
				15 01 00 00 00 00 02 06 01
				15 01 00 00 00 00 02 07 4C
				15 01 00 00 00 00 02 08 01
				15 01 00 00 00 00 02 09 70
				15 01 00 00 00 00 02 0A 01
				15 01 00 00 00 00 02 0B AD
				15 01 00 00 00 00 02 0C 01
				15 01 00 00 00 00 02 0D DE
				15 01 00 00 00 00 02 0E 02
				15 01 00 00 00 00 02 0F 26
				15 01 00 00 00 00 02 10 02
				15 01 00 00 00 00 02 11 5A
				15 01 00 00 00 00 02 12 02
				15 01 00 00 00 00 02 13 5B
				15 01 00 00 00 00 02 14 02
				15 01 00 00 00 00 02 15 8B
				15 01 00 00 00 00 02 16 02
				15 01 00 00 00 00 02 17 B9
				15 01 00 00 00 00 02 18 02
				15 01 00 00 00 00 02 19 D6
				15 01 00 00 00 00 02 1A 03
				15 01 00 00 00 00 02 1B 02
				15 01 00 00 00 00 02 1C 03
				15 01 00 00 00 00 02 1D 1F
				15 01 00 00 00 00 02 1E 03
				15 01 00 00 00 00 02 1F 81
				15 01 00 00 00 00 02 20 03
				15 01 00 00 00 00 02 21 A9
				15 01 00 00 00 00 02 22 03
				15 01 00 00 00 00 02 23 CD
				15 01 00 00 00 00 02 24 03
				15 01 00 00 00 00 02 25 D8
				15 01 00 00 00 00 02 26 03
				15 01 00 00 00 00 02 27 DA
				15 01 00 00 00 00 02 28 03
				15 01 00 00 00 00 02 29 DC
				15 01 00 00 00 00 02 2A 03
				15 01 00 00 00 00 02 2B DC
				15 01 00 00 00 00 02 2D 03
				15 01 00 00 00 00 02 2F DC
				15 01 00 00 00 00 02 30 03
				15 01 00 00 00 00 02 31 DC
				15 01 00 00 00 00 02 32 00
				15 01 00 00 00 00 02 33 BC
				15 01 00 00 00 00 02 34 00
				15 01 00 00 00 00 02 35 CC
				15 01 00 00 00 00 02 36 00
				15 01 00 00 00 00 02 37 EA
				15 01 00 00 00 00 02 38 01
				15 01 00 00 00 00 02 39 06
				15 01 00 00 00 00 02 3A 01
				15 01 00 00 00 00 02 3B 1B
				15 01 00 00 00 00 02 3D 01
				15 01 00 00 00 00 02 3F 2A
				15 01 00 00 00 00 02 40 01
				15 01 00 00 00 00 02 41 39
				15 01 00 00 00 00 02 42 01
				15 01 00 00 00 00 02 43 45
				15 01 00 00 00 00 02 44 01
				15 01 00 00 00 00 02 45 50
				15 01 00 00 00 00 02 46 01
				15 01 00 00 00 00 02 47 76
				15 01 00 00 00 00 02 48 01
				15 01 00 00 00 00 02 49 90
				15 01 00 00 00 00 02 4A 01
				15 01 00 00 00 00 02 4B BB
				15 01 00 00 00 00 02 4C 01
				15 01 00 00 00 00 02 4D DD
				15 01 00 00 00 00 02 4E 02
				15 01 00 00 00 00 02 4F 15
				15 01 00 00 00 00 02 50 02
				15 01 00 00 00 00 02 51 49
				15 01 00 00 00 00 02 52 02
				15 01 00 00 00 00 02 53 4A
				15 01 00 00 00 00 02 54 02
				15 01 00 00 00 00 02 55 79
				15 01 00 00 00 00 02 56 02
				15 01 00 00 00 00 02 58 BF
				15 01 00 00 00 00 02 59 02
				15 01 00 00 00 00 02 5A EB
				15 01 00 00 00 00 02 5B 03
				15 01 00 00 00 00 02 5C 19
				15 01 00 00 00 00 02 5D 03
				15 01 00 00 00 00 02 5E 36
				15 01 00 00 00 00 02 5F 03
				15 01 00 00 00 00 02 60 99
				15 01 00 00 00 00 02 61 03
				15 01 00 00 00 00 02 62 C2
				15 01 00 00 00 00 02 63 03
				15 01 00 00 00 00 02 64 E6
				15 01 00 00 00 00 02 65 03
				15 01 00 00 00 00 02 66 F1
				15 01 00 00 00 00 02 67 03
				15 01 00 00 00 00 02 68 F3
				15 01 00 00 00 00 02 69 03
				15 01 00 00 00 00 02 6A F4
				15 01 00 00 00 00 02 6B 03
				15 01 00 00 00 00 02 6C F4
				15 01 00 00 00 00 02 6D 03
				15 01 00 00 00 00 02 6E F4
				15 01 00 00 00 00 02 6F 03
				15 01 00 00 00 00 02 70 F4
				15 01 00 00 00 00 02 71 00
				15 01 00 00 00 00 02 72 EF
				15 01 00 00 00 00 02 73 00
				15 01 00 00 00 00 02 74 F4
				15 01 00 00 00 00 02 75 01
				15 01 00 00 00 00 02 76 03
				15 01 00 00 00 00 02 77 01
				15 01 00 00 00 00 02 78 11
				15 01 00 00 00 00 02 79 01
				15 01 00 00 00 00 02 7A 1C
				15 01 00 00 00 00 02 7B 01
				15 01 00 00 00 00 02 7C 27
				15 01 00 00 00 00 02 7D 01
				15 01 00 00 00 00 02 7E 31
				15 01 00 00 00 00 02 7F 01
				15 01 00 00 00 00 02 80 3C
				15 01 00 00 00 00 02 81 01
				15 01 00 00 00 00 02 82 46
				15 01 00 00 00 00 02 83 01
				15 01 00 00 00 00 02 84 6A
				15 01 00 00 00 00 02 85 01
				15 01 00 00 00 00 02 86 89
				15 01 00 00 00 00 02 87 01
				15 01 00 00 00 00 02 88 BE
				15 01 00 00 00 00 02 89 01
				15 01 00 00 00 00 02 8A EA
				15 01 00 00 00 00 02 8B 02
				15 01 00 00 00 00 02 8C 2F
				15 01 00 00 00 00 02 8D 02
				15 01 00 00 00 00 02 8E 60
				15 01 00 00 00 00 02 8F 02
				15 01 00 00 00 00 02 90 62
				15 01 00 00 00 00 02 91 02
				15 01 00 00 00 00 02 92 90
				15 01 00 00 00 00 02 93 02
				15 01 00 00 00 00 02 94 BC
				15 01 00 00 00 00 02 95 02
				15 01 00 00 00 00 02 96 DD
				15 01 00 00 00 00 02 97 03
				15 01 00 00 00 00 02 98 0E
				15 01 00 00 00 00 02 99 03
				15 01 00 00 00 00 02 9A 27
				15 01 00 00 00 00 02 9B 03
				15 01 00 00 00 00 02 9C 7A
				15 01 00 00 00 00 02 9D 03
				15 01 00 00 00 00 02 9E A1
				15 01 00 00 00 00 02 9F 03
				15 01 00 00 00 00 02 A0 C8
				15 01 00 00 00 00 02 A2 03
				15 01 00 00 00 00 02 A3 D7
				15 01 00 00 00 00 02 A4 03
				15 01 00 00 00 00 02 A5 DB
				15 01 00 00 00 00 02 A6 03
				15 01 00 00 00 00 02 A7 DC
				15 01 00 00 00 00 02 A9 03
				15 01 00 00 00 00 02 AA DD
				15 01 00 00 00 00 02 AB 03
				15 01 00 00 00 00 02 AC DD
				15 01 00 00 00 00 02 AD 03
				15 01 00 00 00 00 02 AE DD
				15 01 00 00 00 00 02 AF 01
				15 01 00 00 00 00 02 B0 32
				15 01 00 00 00 00 02 B1 01
				15 01 00 00 00 00 02 B2 39
				15 01 00 00 00 00 02 B3 01
				15 01 00 00 00 00 02 B4 45
				15 01 00 00 00 00 02 B5 01
				15 01 00 00 00 00 02 B6 4F
				15 01 00 00 00 00 02 B7 01
				15 01 00 00 00 00 02 B8 59
				15 01 00 00 00 00 02 B9 01
				15 01 00 00 00 00 02 BA 62
				15 01 00 00 00 00 02 BB 01
				15 01 00 00 00 00 02 BC 6A
				15 01 00 00 00 00 02 BD 01
				15 01 00 00 00 00 02 BE 71
				15 01 00 00 00 00 02 BF 01
				15 01 00 00 00 00 02 C0 78
				15 01 00 00 00 00 02 C1 01
				15 01 00 00 00 00 02 C2 92
				15 01 00 00 00 00 02 C3 01
				15 01 00 00 00 00 02 C4 A8
				15 01 00 00 00 00 02 C5 01
				15 01 00 00 00 00 02 C6 CD
				15 01 00 00 00 00 02 C7 01
				15 01 00 00 00 00 02 C8 EA
				15 01 00 00 00 00 02 C9 02
				15 01 00 00 00 00 02 CA 1D
				15 01 00 00 00 00 02 CB 02
				15 01 00 00 00 00 02 CC 4E
				15 01 00 00 00 00 02 CD 02
				15 01 00 00 00 00 02 CE 4F
				15 01 00 00 00 00 02 CF 02
				15 01 00 00 00 00 02 D0 7D
				15 01 00 00 00 00 02 D1 02
				15 01 00 00 00 00 02 D2 C2
				15 01 00 00 00 00 02 D3 02
				15 01 00 00 00 00 02 D4 F1
				15 01 00 00 00 00 02 D5 03
				15 01 00 00 00 00 02 D6 24
				15 01 00 00 00 00 02 D7 03
				15 01 00 00 00 00 02 D8 3E
				15 01 00 00 00 00 02 D9 03
				15 01 00 00 00 00 02 DA 91
				15 01 00 00 00 00 02 DB 03
				15 01 00 00 00 00 02 DC B8
				15 01 00 00 00 00 02 DD 03
				15 01 00 00 00 00 02 DE DF
				15 01 00 00 00 00 02 DF 03
				15 01 00 00 00 00 02 E0 EE
				15 01 00 00 00 00 02 E1 03
				15 01 00 00 00 00 02 E2 F1
				15 01 00 00 00 00 02 E3 03
				15 01 00 00 00 00 02 E4 F3
				15 01 00 00 00 00 02 E5 03
				15 01 00 00 00 00 02 E6 F3
				15 01 00 00 00 00 02 E7 03
				15 01 00 00 00 00 02 E8 F3
				15 01 00 00 00 00 02 E9 03
				15 01 00 00 00 00 02 EA F3
				15 01 00 00 00 00 02 FF 24
				15 01 00 00 00 00 02 FB 01
				15 01 00 00 00 00 02 86 39
				15 01 00 00 00 00 02 87 1B
				15 01 00 00 00 00 02 88 39
				15 01 00 00 00 00 02 89 1B
				15 01 00 00 00 00 02 8C 01
				15 01 00 00 00 00 02 FF 10
				15 01 00 00 00 00 02 35 00
				39 01 00 00 00 00 03 44 03 00
				15 01 00 00 00 00 02 FF E0
				15 01 00 00 00 00 02 FB 01
				15 01 00 00 00 00 02 B5 86
				15 01 00 00 00 00 02 B6 77
				15 01 00 00 00 00 02 B8 AD
				15 01 00 00 00 00 02 FF 20
				15 01 00 00 00 00 02 FB 01
				15 01 00 00 00 00 02 10 04
				15 01 00 00 00 00 02 FF 10
				05 01 00 00 1E 00 01 11];
		qcom,mdss-dsi-on-command = [05 01 00 00 00 00 01 29];
		qcom,mdss-dsi-off-command = [15 01 00 00 00 00 02 FF 10
				05 01 00 00 14 00 01 28
				05 01 00 00 50 00 01 10];
		qcom,mdss-dsi-on-command-state = "dsi_lp_mode";
		qcom,mdss-dsi-off-command-state = "dsi_hs_mode";
		qcom,mdss-dsi-te-pin-select = <1>;
		qcom,mdss-dsi-wr-mem-start = <0x2c>;
		qcom,mdss-dsi-wr-mem-continue = <0x3c>;
		qcom,mdss-dsi-te-dcs-command = <1>;
		qcom,mdss-dsi-te-check-enable;
		qcom,mdss-dsi-te-using-te-pin;
		qcom,mdss-dsi-lane-0-state;
		qcom,mdss-dsi-lane-1-state;
		qcom,mdss-dsi-lane-2-state;
		qcom,mdss-dsi-lane-3-state;
		qcom,mdss-dsi-panel-timings = [E6 38 26 00 68 66 32 3C 2C 03 04 00];
		qcom,mdss-dsi-t-clk-post = <0x21>;
		qcom,mdss-dsi-t-clk-pre = <0x2B>;
		qcom,mdss-dsi-tx-eot-append;
		qcom,mdss-dsi-lp11-init;
		qcom,mdss-dsi-bl-min-level = <1>;
		qcom,mdss-dsi-bl-max-level = <4095>;
		qcom,mdss-brightness-max-level = <4095>;
		qcom,mdss-dsi-bl-pmic-control-type = "bl_ctrl_wled";
		qcom,qpnp-lab-limit-maximum-current = <200>;
		qcom,qpnp-ibb-limit-maximum-current = <800>;

		somc,mdss-dsi-disp-on-in-hs = <0>;
		somc,mdss-dsi-wait-time-before-on-cmd = <0>;
		somc,platform-regulator-settings = [03 03 03 00 20 00 01];
		somc,mdss-dsi-lane-config = [02 00 EF 00 20 00 00 01 FF
				02 00 EF 00 40 00 00 01 FF
				02 00 EF 40 20 00 00 01 FF
				02 00 EF 40 00 00 00 01 FF
				00 00 45 80 00 00 00 01 97];
		somc,disp-en-on-pre = <1>;
		somc,pw-on-rst-seq = <0 20>, <1 1>, <0 1>, <1 10>;
		somc,disp-en-off-post = <10>;
		somc,pw-off-rst-seq = <0 1>;
		somc,pw-down-period = <100>;
		somc,lab-output-voltage = <5600000>;
		somc,ibb-output-voltage = <5600000>;
		somc,lcd-id = <1>;
		somc,lcd-id-adc = <1236000 1395000>;
		somc,mdss-dsi-master;

		somc,change-fps-enable;
		somc,change-fps-command = [15 01 00 00 00 00 02 FF 24
				15 01 00 00 00 00 02 92 8F
				15 01 00 00 00 00 02 FF 10
				39 01 00 00 00 00 03 44 03 00];
		somc,display-clock = <16660000>;
		somc,driver-ic-vbp = <6>;
		somc,driver-ic-vfp = <2>;
		somc,change-fps-rtn-adj;
		somc,change-fps-rtn-pos = <1 1>;
		somc,fps-threshold = <47400>;
		somc,te-c-mode-60fps = <0x03 0x00>;
		somc,te-c-mode-45fps = <0x04 0xFF>;
		somc,te-c-mode-pos = <3 1>;

		somc,mdss-dsi-lock-command = [15 01 00 00 00 00 02 FF 10
				15 01 00 00 00 00 02 FB 01
				15 01 00 00 00 00 02 F0 55
				15 01 00 00 00 00 02 F1 AA
				15 01 00 00 01 00 02 F2 66];

		somc,mdss-dsi-unlock-command = [15 01 00 00 00 00 02 FF 10
				15 01 00 00 00 00 02 FB 01
				15 01 00 00 00 00 02 F0 AA
				15 01 00 00 00 00 02 F1 55
				15 01 00 00 01 00 02 F2 99];

		somc,mdss-dsi-pcc-enable;
		somc,mdss-dsi-uv-command = [06 01 00 00 00 00 01 DA
			06 01 00 00 00 00 01 DB];
		somc,mdss-dsi-uv-param-type = <4>;
		somc,mdss-dsi-pcc-table-size = <225>;
		somc,mdss-dsi-pcc-table = <
			0x00 0x01 0x38 0x3B 0x38 0x3B 0x3D00 0x6B80 0x8000
			0x00 0x02 0x34 0x37 0x38 0x3B 0x4200 0x6B00 0x8000
			0x00 0x03 0x30 0x33 0x38 0x3B 0x4700 0x6A80 0x8000
			0x00 0x04 0x2C 0x2F 0x38 0x3B 0x4C80 0x6A00 0x8000
			0x00 0x05 0x28 0x2B 0x38 0x3B 0x5280 0x6A00 0x8000
			0x00 0x06 0x24 0x27 0x38 0x3B 0x5700 0x6980 0x8000
			0x00 0x07 0x20 0x23 0x38 0x3B 0x5D00 0x6900 0x8000
			0x00 0x08 0x1C 0x1F 0x38 0x3B 0x6280 0x6900 0x8000
			0x00 0x09 0x18 0x1B 0x38 0x3B 0x6880 0x6880 0x8000
			0x00 0x0A 0x14 0x17 0x38 0x3B 0x6E00 0x6800 0x8000
			0x00 0x0B 0x10 0x13 0x38 0x3B 0x7480 0x6880 0x8000
			0x00 0x0C 0x0C 0x0F 0x38 0x3B 0x7B00 0x6800 0x8000
			0x00 0x0D 0x08 0x0B 0x38 0x3B 0x8000 0x6580 0x7E00
			0x00 0x0E 0x04 0x07 0x38 0x3B 0x8000 0x5E00 0x7600
			0x00 0x0F 0x00 0x03 0x38 0x3B 0x8000 0x5580 0x6C80
			0x00 0x10 0x38 0x3B 0x34 0x37 0x4300 0x6F00 0x8000
			0x00 0x11 0x34 0x37 0x34 0x37 0x4880 0x6E80 0x8000
			0x00 0x12 0x30 0x33 0x34 0x37 0x4D80 0x6E00 0x8000
			0x00 0x13 0x2C 0x2F 0x34 0x37 0x5280 0x6D80 0x8000
			0x00 0x14 0x28 0x2B 0x34 0x37 0x5700 0x6D80 0x8000
			0x00 0x15 0x24 0x27 0x34 0x37 0x5C80 0x6D00 0x8000
			0x00 0x16 0x20 0x23 0x34 0x37 0x6200 0x6C80 0x8000
			0x00 0x17 0x1C 0x1F 0x34 0x37 0x6780 0x6C00 0x8000
			0x00 0x18 0x18 0x1B 0x34 0x37 0x6D00 0x6B80 0x8000
			0x00 0x19 0x14 0x17 0x34 0x37 0x7300 0x6B80 0x8000
			0x00 0x1A 0x10 0x13 0x34 0x37 0x7900 0x6B00 0x8000
			0x00 0x1B 0x0C 0x0F 0x34 0x37 0x8000 0x6A80 0x8000
			0x00 0x1C 0x08 0x0B 0x34 0x37 0x8000 0x6400 0x7900
			0x00 0x1D 0x04 0x07 0x34 0x37 0x8000 0x5C00 0x7180
			0x00 0x1E 0x00 0x03 0x34 0x37 0x8000 0x5300 0x6800
			0x00 0x1F 0x38 0x3B 0x30 0x33 0x4900 0x7300 0x8000
			0x00 0x20 0x34 0x37 0x30 0x33 0x4E00 0x7280 0x8000
			0x00 0x21 0x30 0x33 0x30 0x33 0x5280 0x7200 0x8000
			0x00 0x22 0x2C 0x2F 0x30 0x33 0x5700 0x7100 0x8000
			0x00 0x23 0x28 0x2B 0x30 0x33 0x5C80 0x7080 0x8000
			0x00 0x24 0x24 0x27 0x30 0x33 0x6180 0x7000 0x8000
			0x00 0x25 0x20 0x23 0x30 0x33 0x6680 0x6F80 0x8000
			0x00 0x26 0x1C 0x1F 0x30 0x33 0x6B80 0x6F80 0x8000
			0x00 0x27 0x18 0x1B 0x30 0x33 0x7180 0x6F00 0x8000
			0x00 0x28 0x14 0x17 0x30 0x33 0x7700 0x6E80 0x8000
			0x00 0x29 0x10 0x13 0x30 0x33 0x7E00 0x6E00 0x8000
			0x00 0x2A 0x0C 0x0F 0x30 0x33 0x8000 0x6980 0x7C00
			0x00 0x2B 0x08 0x0B 0x30 0x33 0x8000 0x6280 0x7500
			0x00 0x2C 0x04 0x07 0x30 0x33 0x8000 0x5A80 0x6D00
			0x00 0x2D 0x00 0x03 0x30 0x33 0x8000 0x5080 0x6400
			0x00 0x2E 0x38 0x3B 0x2C 0x2F 0x4E80 0x7680 0x8000
			0x00 0x2F 0x34 0x37 0x2C 0x2F 0x5300 0x7600 0x8000
			0x00 0x30 0x30 0x33 0x2C 0x2F 0x5700 0x7580 0x8000
			0x00 0x31 0x2C 0x2F 0x2C 0x2F 0x5C00 0x7480 0x8000
			0x00 0x32 0x28 0x2B 0x2C 0x2F 0x6100 0x7400 0x8000
			0x00 0x33 0x24 0x27 0x2C 0x2F 0x6600 0x7380 0x8000
			0x00 0x34 0x20 0x23 0x2C 0x2F 0x6B00 0x7300 0x8000
			0x00 0x35 0x1C 0x1F 0x2C 0x2F 0x7000 0x7280 0x8000
			0x00 0x36 0x18 0x1B 0x2C 0x2F 0x7600 0x7200 0x8000
			0x00 0x37 0x14 0x17 0x2C 0x2F 0x7B80 0x7180 0x8000
			0x00 0x38 0x10 0x13 0x2C 0x2F 0x8000 0x6F00 0x7E80
			0x00 0x39 0x0C 0x0F 0x2C 0x2F 0x8000 0x6880 0x7800
			0x00 0x3A 0x08 0x0B 0x2C 0x2F 0x8000 0x6100 0x7180
			0x00 0x3B 0x04 0x07 0x2C 0x2F 0x8000 0x5800 0x6980
			0x00 0x3C 0x00 0x03 0x2C 0x2F 0x8000 0x4E00 0x6080
			0x00 0x3D 0x38 0x3B 0x28 0x2B 0x5300 0x7A80 0x8000
			0x00 0x3E 0x34 0x37 0x28 0x2B 0x5700 0x7980 0x8000
			0x00 0x3F 0x30 0x33 0x28 0x2B 0x5C00 0x7880 0x8000
			0x00 0x40 0x2C 0x2F 0x28 0x2B 0x6080 0x7800 0x8000
			0x00 0x41 0x28 0x2B 0x28 0x2B 0x6500 0x7780 0x8000
			0x00 0x42 0x24 0x27 0x28 0x2B 0x6A00 0x7700 0x8000
			0x00 0x43 0x20 0x23 0x28 0x2B 0x6F80 0x7600 0x8000
			0x00 0x44 0x1C 0x1F 0x28 0x2B 0x7480 0x7580 0x8000
			0x00 0x45 0x18 0x1B 0x28 0x2B 0x7980 0x7500 0x8000
			0x00 0x46 0x14 0x17 0x28 0x2B 0x8000 0x7480 0x8000
			0x00 0x47 0x10 0x13 0x28 0x2B 0x8000 0x6E80 0x7B00
			0x00 0x48 0x0C 0x0F 0x28 0x2B 0x8000 0x6780 0x7500
			0x00 0x49 0x08 0x0B 0x28 0x2B 0x8000 0x5F80 0x6D80
			0x00 0x4A 0x04 0x07 0x28 0x2B 0x8000 0x5600 0x6600
			0x00 0x4B 0x00 0x03 0x28 0x2B 0x8000 0x4B00 0x5D00
			0x00 0x4C 0x38 0x3B 0x24 0x27 0x5700 0x7E80 0x8000
			0x00 0x4D 0x34 0x37 0x24 0x27 0x5B80 0x7E00 0x8000
			0x00 0x4E 0x30 0x33 0x24 0x27 0x6000 0x7C80 0x8000
			0x00 0x4F 0x2C 0x2F 0x24 0x27 0x6480 0x7C00 0x8000
			0x00 0x50 0x28 0x2B 0x24 0x27 0x6980 0x7B00 0x8000
			0x00 0x51 0x24 0x27 0x24 0x27 0x6D80 0x7A00 0x8000
			0x00 0x52 0x20 0x23 0x24 0x27 0x7300 0x7980 0x8000
			0x00 0x53 0x1C 0x1F 0x24 0x27 0x7800 0x7900 0x8000
			0x00 0x54 0x18 0x1B 0x24 0x27 0x7E00 0x7800 0x8000
			0x00 0x55 0x14 0x17 0x24 0x27 0x8000 0x7400 0x7D00
			0x00 0x56 0x10 0x13 0x24 0x27 0x8000 0x6D80 0x7780
			0x00 0x57 0x0C 0x0F 0x24 0x27 0x8000 0x6680 0x7180
			0x00 0x58 0x08 0x0B 0x24 0x27 0x8000 0x5D80 0x6B00
			0x00 0x59 0x04 0x07 0x24 0x27 0x8000 0x5400 0x6300
			0x00 0x5A 0x00 0x03 0x24 0x27 0x8000 0x4780 0x5980
			0x00 0x5B 0x38 0x3B 0x20 0x23 0x5800 0x8000 0x7E00
			0x00 0x5C 0x34 0x37 0x20 0x23 0x5D80 0x8000 0x7F00
			0x00 0x5D 0x30 0x33 0x20 0x23 0x6300 0x8000 0x7F80
			0x00 0x5E 0x2C 0x2F 0x20 0x23 0x6880 0x8000 0x8000
			0x00 0x5F 0x28 0x2B 0x20 0x23 0x6C80 0x7F00 0x8000
			0x00 0x60 0x24 0x27 0x20 0x23 0x7180 0x7E00 0x8000
			0x00 0x61 0x20 0x23 0x20 0x23 0x7680 0x7D00 0x8000
			0x00 0x62 0x1C 0x1F 0x20 0x23 0x7B80 0x7C80 0x8000
			0x00 0x63 0x18 0x1B 0x20 0x23 0x8000 0x7980 0x7F00
			0x00 0x64 0x14 0x17 0x20 0x23 0x8000 0x7380 0x7A80
			0x00 0x65 0x10 0x13 0x20 0x23 0x8000 0x6D00 0x7500
			0x00 0x66 0x0C 0x0F 0x20 0x23 0x8000 0x6580 0x6F00
			0x00 0x67 0x08 0x0B 0x20 0x23 0x8000 0x5C00 0x6800
			0x00 0x68 0x04 0x07 0x20 0x23 0x8000 0x5180 0x6080
			0x00 0x69 0x00 0x03 0x20 0x23 0x8000 0x4400 0x5680
			0x00 0x6A 0x38 0x3B 0x1C 0x1F 0x5600 0x8000 0x7B00
			0x00 0x6B 0x34 0x37 0x1C 0x1F 0x5C00 0x8000 0x7C00
			0x00 0x6C 0x30 0x33 0x1C 0x1F 0x6200 0x8000 0x7D00
			0x00 0x6D 0x2C 0x2F 0x1C 0x1F 0x6780 0x8000 0x7D80
			0x00 0x6E 0x28 0x2B 0x1C 0x1F 0x6D00 0x8000 0x7E00
			0x00 0x6F 0x24 0x27 0x1C 0x1F 0x7300 0x8000 0x7F00
			0x00 0x70 0x20 0x23 0x1C 0x1F 0x7900 0x8000 0x7F80
			0x00 0x71 0x18 0x1B 0x1C 0x1F 0x8000 0x7980 0x7C80
			0x00 0x72 0x14 0x17 0x1C 0x1F 0x8000 0x7300 0x7780
			0x00 0x73 0x10 0x13 0x1C 0x1F 0x8000 0x6C00 0x7200
			0x00 0x74 0x0C 0x0F 0x1C 0x1F 0x8000 0x6400 0x6B80
			0x00 0x75 0x08 0x0B 0x1C 0x1F 0x8000 0x5A80 0x6500
			0x00 0x76 0x04 0x07 0x1C 0x1F 0x8000 0x5000 0x5D80
			0x00 0x77 0x00 0x03 0x1C 0x1F 0x8000 0x4100 0x5400
			0x00 0x78 0x38 0x3B 0x18 0x1B 0x5480 0x8000 0x7800
			0x00 0x79 0x34 0x37 0x18 0x1B 0x5B00 0x8000 0x7880
			0x00 0x7A 0x30 0x33 0x18 0x1B 0x6100 0x8000 0x7A00
			0x00 0x7B 0x2C 0x2F 0x18 0x1B 0x6700 0x8000 0x7B00
			0x00 0x7C 0x28 0x2B 0x18 0x1B 0x6C80 0x8000 0x7B80
			0x00 0x7D 0x24 0x27 0x18 0x1B 0x7280 0x8000 0x7C80
			0x00 0x7E 0x20 0x23 0x18 0x1B 0x7880 0x8000 0x7D00
			0x00 0x7F 0x1C 0x1F 0x18 0x1B 0x8000 0x8000 0x7D80
			0x00 0x80 0x18 0x1B 0x18 0x1B 0x8000 0x7980 0x7A00
			0x00 0x81 0x14 0x17 0x18 0x1B 0x8000 0x7300 0x7500
			0x00 0x82 0x10 0x13 0x18 0x1B 0x8000 0x6B00 0x6F80
			0x00 0x83 0x0C 0x0F 0x18 0x1B 0x8000 0x6300 0x6980
			0x00 0x84 0x08 0x0B 0x18 0x1B 0x8000 0x5900 0x6300
			0x00 0x85 0x04 0x07 0x18 0x1B 0x8000 0x4D00 0x5A80
			0x00 0x86 0x00 0x03 0x18 0x1B 0x8000 0x3D00 0x5100
			0x00 0x87 0x38 0x3B 0x14 0x17 0x5300 0x8000 0x7500
			0x00 0x88 0x34 0x37 0x14 0x17 0x5980 0x8000 0x7600
			0x00 0x89 0x30 0x33 0x14 0x17 0x5F80 0x8000 0x7700
			0x00 0x8A 0x2C 0x2F 0x14 0x17 0x6600 0x8000 0x7800
			0x00 0x8B 0x28 0x2B 0x14 0x17 0x6B80 0x8000 0x7880
			0x00 0x8C 0x24 0x27 0x14 0x17 0x7200 0x8000 0x7A00
			0x00 0x8D 0x20 0x23 0x14 0x17 0x7800 0x8000 0x7A80
			0x00 0x8E 0x1C 0x1F 0x14 0x17 0x7F00 0x8000 0x7B80
			0x00 0x8F 0x18 0x1B 0x14 0x17 0x8000 0x7900 0x7700
			0x00 0x90 0x14 0x17 0x14 0x17 0x8000 0x7280 0x7280
			0x00 0x91 0x10 0x13 0x14 0x17 0x8000 0x7280 0x7280
			0x00 0x92 0x0C 0x0F 0x14 0x17 0x8000 0x6A80 0x6D00
			0x00 0x93 0x08 0x0B 0x14 0x17 0x8000 0x6180 0x6700
			0x00 0x94 0x04 0x07 0x14 0x17 0x8000 0x4A80 0x5800
			0x00 0x95 0x00 0x03 0x14 0x17 0x8000 0x3980 0x4E80
			0x00 0x96 0x38 0x3B 0x10 0x13 0x5180 0x8000 0x7280
			0x00 0x97 0x34 0x37 0x10 0x13 0x5800 0x8000 0x7380
			0x00 0x98 0x30 0x33 0x10 0x13 0x5E80 0x8000 0x7480
			0x00 0x99 0x2C 0x2F 0x10 0x13 0x6500 0x8000 0x7580
			0x00 0x9A 0x28 0x2B 0x10 0x13 0x6B80 0x8000 0x7680
			0x00 0x9B 0x24 0x27 0x10 0x13 0x7180 0x8000 0x7700
			0x00 0x9C 0x20 0x23 0x10 0x13 0x7800 0x8000 0x7800
			0x00 0x9D 0x1C 0x1F 0x10 0x13 0x7F00 0x8000 0x7880
			0x00 0x9E 0x18 0x1B 0x10 0x13 0x8000 0x7900 0x7500
			0x00 0x9F 0x14 0x17 0x10 0x13 0x8000 0x7200 0x7080
			0x00 0xA0 0x10 0x13 0x10 0x13 0x8000 0x7200 0x7080
			0x00 0xA1 0x0C 0x0F 0x10 0x13 0x8000 0x6980 0x6A80
			0x00 0xA2 0x08 0x0B 0x10 0x13 0x8000 0x6080 0x6500
			0x00 0xA3 0x04 0x07 0x10 0x13 0x8000 0x4800 0x5600
			0x00 0xA4 0x00 0x03 0x10 0x13 0x8000 0x3500 0x4C00
			0x00 0xA5 0x38 0x3B 0x0C 0x0F 0x5000 0x8000 0x7000
			0x00 0xA6 0x34 0x37 0x0C 0x0F 0x5600 0x8000 0x7180
			0x00 0xA7 0x30 0x33 0x0C 0x0F 0x5D00 0x8000 0x7280
			0x00 0xA8 0x2C 0x2F 0x0C 0x0F 0x6400 0x8000 0x7380
			0x00 0xA9 0x28 0x2B 0x0C 0x0F 0x6A80 0x8000 0x7400
			0x00 0xAA 0x24 0x27 0x0C 0x0F 0x7100 0x8000 0x7500
			0x00 0xAB 0x20 0x23 0x0C 0x0F 0x7780 0x8000 0x7600
			0x00 0xAC 0x1C 0x1F 0x0C 0x0F 0x7F00 0x8000 0x7680
			0x00 0xAD 0x18 0x1B 0x0C 0x0F 0x8000 0x7900 0x7300
			0x00 0xAE 0x14 0x17 0x0C 0x0F 0x8000 0x7180 0x6E00
			0x00 0xAF 0x10 0x13 0x0C 0x0F 0x8000 0x7180 0x6E00
			0x00 0xB0 0x0C 0x0F 0x0C 0x0F 0x8000 0x6900 0x6900
			0x00 0xB1 0x08 0x0B 0x0C 0x0F 0x8000 0x5F00 0x6380
			0x00 0xB2 0x04 0x07 0x0C 0x0F 0x8000 0x4500 0x5400
			0x00 0xB3 0x00 0x03 0x0C 0x0F 0x8000 0x3080 0x4A00
			0x00 0xB4 0x38 0x3B 0x08 0x0B 0x4D80 0x8000 0x6D80
			0x00 0xB5 0x34 0x37 0x08 0x0B 0x5480 0x8000 0x6E80
			0x00 0xB6 0x30 0x33 0x08 0x0B 0x5C00 0x8000 0x7000
			0x00 0xB7 0x2C 0x2F 0x08 0x0B 0x6300 0x8000 0x7100
			0x00 0xB8 0x28 0x2B 0x08 0x0B 0x6A00 0x8000 0x7200
			0x00 0xB9 0x24 0x27 0x08 0x0B 0x7080 0x8000 0x7300
			0x00 0xBA 0x20 0x23 0x08 0x0B 0x7700 0x8000 0x7400
			0x00 0xBB 0x1C 0x1F 0x08 0x0B 0x7F00 0x8000 0x7480
			0x00 0xBC 0x18 0x1B 0x08 0x0B 0x8000 0x7900 0x7180
			0x00 0xBD 0x14 0x17 0x08 0x0B 0x8000 0x7100 0x6C00
			0x00 0xBE 0x10 0x13 0x08 0x0B 0x8000 0x7100 0x6C00
			0x00 0xBF 0x0C 0x0F 0x08 0x0B 0x8000 0x6880 0x6780
			0x00 0xC0 0x08 0x0B 0x08 0x0B 0x8000 0x5D80 0x6180
			0x00 0xC1 0x04 0x07 0x08 0x0B 0x8000 0x4280 0x5200
			0x00 0xC2 0x00 0x03 0x08 0x0B 0x8000 0x2B00 0x4780
			0x00 0xC3 0x38 0x3B 0x04 0x07 0x4B80 0x8000 0x6B80
			0x00 0xC4 0x34 0x37 0x04 0x07 0x5300 0x8000 0x6C80
			0x00 0xC5 0x30 0x33 0x04 0x07 0x5A80 0x8000 0x6D80
			0x00 0xC6 0x2C 0x2F 0x04 0x07 0x6200 0x8000 0x6F80
			0x00 0xC7 0x28 0x2B 0x04 0x07 0x6900 0x8000 0x7080
			0x00 0xC8 0x24 0x27 0x04 0x07 0x7000 0x8000 0x7100
			0x00 0xC9 0x20 0x23 0x04 0x07 0x7680 0x8000 0x7200
			0x00 0xCA 0x1C 0x1F 0x04 0x07 0x7E80 0x8000 0x7300
			0x00 0xCB 0x18 0x1B 0x04 0x07 0x8000 0x7880 0x6F80
			0x00 0xCC 0x14 0x17 0x04 0x07 0x8000 0x7080 0x6A80
			0x00 0xCD 0x10 0x13 0x04 0x07 0x8000 0x6780 0x6580
			0x00 0xCE 0x0C 0x0F 0x04 0x07 0x8000 0x5C80 0x6080
			0x00 0xCF 0x08 0x0B 0x04 0x07 0x8000 0x5000 0x5880
			0x00 0xD0 0x04 0x07 0x04 0x07 0x8000 0x3F80 0x5080
			0x00 0xD1 0x00 0x03 0x04 0x07 0x8000 0x2800 0x4580
			0x00 0xD2 0x38 0x3B 0x00 0x03 0x4900 0x8000 0x6A00
			0x00 0xD3 0x34 0x37 0x00 0x03 0x5180 0x8000 0x6A80
			0x00 0xD4 0x30 0x33 0x00 0x03 0x5900 0x8000 0x6C00
			0x00 0xD5 0x2C 0x2F 0x00 0x03 0x6080 0x8000 0x6D00
			0x00 0xD6 0x28 0x2B 0x00 0x03 0x6800 0x8000 0x6E00
			0x00 0xD7 0x24 0x27 0x00 0x03 0x6F80 0x8000 0x6F80
			0x00 0xD8 0x20 0x23 0x00 0x03 0x7680 0x8000 0x7080
			0x00 0xD9 0x1C 0x1F 0x00 0x03 0x7E80 0x8000 0x7180
			0x00 0xDA 0x18 0x1B 0x00 0x03 0x8000 0x7880 0x6D80
			0x00 0xDB 0x14 0x17 0x00 0x03 0x8000 0x7000 0x6980
			0x00 0xDC 0x10 0x13 0x00 0x03 0x8000 0x6680 0x6400
			0x00 0xDD 0x0C 0x0F 0x00 0x03 0x8000 0x5B00 0x5E80
			0x00 0xDE 0x08 0x0B 0x00 0x03 0x8000 0x4E00 0x5700
			0x00 0xDF 0x04 0x07 0x00 0x03 0x8000 0x3B80 0x4F00
			0x00 0xE0 0x00 0x03 0x00 0x03 0x8000 0x2800 0x4380
			0xFF 0x00 0x00 0x3B 0x00 0x3B 0x8000 0x8000 0x8000>;
	};

	dsi_auo_novatek_fullhd_cmd: somc,auo_novatek_fullhd_cmd_panel {
		qcom,mdss-dsi-panel-name = "4";
		qcom,mdss-dsi-panel-controller = <&mdss_dsi0>;
		qcom,mdss-dsi-panel-destination = "display_1";
		qcom,mdss-dsi-panel-type = "dsi_cmd_mode";
		qcom,mdss-dsi-panel-width = <1080>;
		qcom,mdss-dsi-panel-height = <1920>;
		qcom,mdss-dsi-bpp = <24>;
		qcom,mdss-dsi-h-back-porch = <8>;
		qcom,mdss-dsi-h-pulse-width = <8>;
		qcom,mdss-dsi-h-front-porch = <56>;
		qcom,mdss-dsi-v-back-porch = <8>;
		qcom,mdss-dsi-v-pulse-width = <2>;
		qcom,mdss-dsi-v-front-porch = <233>;
		qcom,mdss-pan-physical-width-dimension = <64>;
		qcom,mdss-pan-physical-height-dimension = <114>;
		qcom,mdss-dsi-panel-framerate = <60>;
		qcom,mdss-dsi-virtual-channel-id = <0>;
		qcom,mdss-dsi-stream = <0>;
		qcom,mdss-dsi-h-sync-skew = <0>;
		qcom,mdss-dsi-h-left-border = <0>;
		qcom,mdss-dsi-h-right-border = <0>;
		qcom,mdss-dsi-v-top-border = <0>;
		qcom,mdss-dsi-v-bottom-border = <0>;
		qcom,mdss-dsi-underflow-color = <0x0>;
		qcom,mdss-dsi-border-color = <0>;
		qcom,mdss-dsi-h-sync-pulse = <1>;
		qcom,mdss-dsi-traffic-mode = "non_burst_sync_event";
		qcom,mdss-dsi-bllp-eof-power-mode;
		qcom,mdss-dsi-bllp-power-mode;
		qcom,mdss-dsi-dma-trigger = "trigger_sw";
		qcom,mdss-dsi-mdp-trigger = "none";
		somc,mdss-dsi-init-command = [15 01 00 00 00 00 02 FF E0
				15 01 00 00 00 00 02 FB 01
				15 01 00 00 00 00 02 B5 86
				15 01 00 00 00 00 02 B6 77
				15 01 00 00 00 00 02 B8 AD
				15 01 00 00 00 00 02 FF 20
				15 01 00 00 00 00 02 FB 01
				15 01 00 00 00 00 02 2D 94
				15 01 00 00 00 00 02 FF 24
				15 01 00 00 00 00 02 FB 01
				15 01 00 00 00 00 02 C6 00
				15 01 00 00 00 00 02 92 8B
				15 01 00 00 00 00 02 C5 32
				15 01 00 00 00 00 02 FF 10
				15 01 00 00 00 00 02 35 00
				39 01 00 00 00 00 03 44 03 00
				39 01 00 00 00 00 04 3B 03 30 06
				15 01 00 00 01 00 02 BB 10
				05 01 00 00 1E 00 01 11];
		qcom,mdss-dsi-on-command = [05 01 00 00 28 00 01 29];
		qcom,mdss-dsi-off-command = [05 01 00 00 00 00 01 28
				05 01 00 00 64 00 01 10];
		qcom,mdss-dsi-on-command-state = "dsi_lp_mode";
		qcom,mdss-dsi-off-command-state = "dsi_hs_mode";
		qcom,mdss-dsi-te-pin-select = <1>;
		qcom,mdss-dsi-wr-mem-start = <0x2c>;
		qcom,mdss-dsi-wr-mem-continue = <0x3c>;
		qcom,mdss-dsi-te-dcs-command = <1>;
		qcom,mdss-dsi-te-check-enable;
		qcom,mdss-dsi-te-using-te-pin;
		qcom,mdss-dsi-lane-0-state;
		qcom,mdss-dsi-lane-1-state;
		qcom,mdss-dsi-lane-2-state;
		qcom,mdss-dsi-lane-3-state;
		qcom,mdss-dsi-panel-timings = [E6 38 26 00 68 66 32 3C 2C 03 04 00];
		qcom,mdss-dsi-t-clk-post = <0x21>;
		qcom,mdss-dsi-t-clk-pre = <0x2B>;
		qcom,mdss-dsi-tx-eot-append;
		qcom,mdss-dsi-lp11-init;
		qcom,mdss-dsi-bl-min-level = <1>;
		qcom,mdss-dsi-bl-max-level = <4095>;
		qcom,mdss-brightness-max-level = <4095>;
		qcom,mdss-dsi-bl-pmic-control-type = "bl_ctrl_wled";
		qcom,qpnp-lab-limit-maximum-current = <200>;
		qcom,qpnp-ibb-limit-maximum-current = <800>;

		somc,mdss-dsi-disp-on-in-hs = <0>;
		somc,mdss-dsi-wait-time-before-on-cmd = <0>;
		somc,platform-regulator-settings = [03 03 03 00 20 00 01];
		somc,mdss-dsi-lane-config = [02 00 EF 00 20 00 00 01 FF
				02 00 EF 00 40 00 00 01 FF
				02 00 EF 40 20 00 00 01 FF
				02 00 EF 40 00 00 00 01 FF
				00 00 45 80 00 00 00 01 97];
		somc,disp-en-on-pre = <1>;
		somc,pw-on-rst-seq = <0 20>, <1 10>;
		somc,disp-en-off-post = <70>;
		somc,pw-off-rst-seq = <0 0>;
		somc,pw-down-period = <100>;
		somc,lab-output-voltage = <5400000>;
		somc,ibb-output-voltage = <5400000>;
		somc,lcd-id = <1>;
		somc,lcd-id-adc = <1087000 1231000>;
		somc,mdss-dsi-master;

		somc,change-fps-enable;
		somc,change-fps-command = [15 01 00 00 00 00 02 FF 24
				15 01 00 00 00 00 02 92 8B
				15 01 00 00 00 00 02 FF 10
				39 01 00 00 00 00 03 44 03 00];
		somc,display-clock = <16660000>;
		somc,driver-ic-vbp = <48>;
		somc,driver-ic-vfp = <6>;
		somc,change-fps-rtn-adj;
		somc,change-fps-rtn-pos = <1 1>;
		somc,fps-threshold = <47400>;
		somc,te-c-mode-60fps = <0x03 0x00>;
		somc,te-c-mode-45fps = <0x04 0xFF>;
		somc,te-c-mode-pos = <3 1>;

		somc,mdss-dsi-lock-command = [15 01 00 00 00 00 02 FF 10
				15 01 00 00 00 00 02 FB 01
				15 01 00 00 00 00 02 F0 55
				15 01 00 00 00 00 02 F1 AA
				15 01 00 00 01 00 02 F2 66];

		somc,mdss-dsi-unlock-command = [15 01 00 00 00 00 02 FF 10
				15 01 00 00 00 00 02 FB 01
				15 01 00 00 00 00 02 F0 AA
				15 01 00 00 00 00 02 F1 55
				15 01 00 00 01 00 02 F2 99];

		somc,mdss-dsi-pcc-enable;
		somc,mdss-dsi-uv-command = [06 01 00 00 00 00 01 DA
			06 01 00 00 00 00 01 DB];
		somc,mdss-dsi-uv-param-type = <4>;
		somc,mdss-dsi-pcc-table-size = <225>;
		somc,mdss-dsi-pcc-table = <
			0x00 0x01 0x38 0x3B 0x38 0x3B 0x5600 0x7280 0x8000
			0x00 0x02 0x34 0x37 0x38 0x3B 0x5980 0x7280 0x8000
			0x00 0x03 0x30 0x33 0x38 0x3B 0x5D80 0x7200 0x8000
			0x00 0x04 0x2C 0x2F 0x38 0x3B 0x6180 0x7180 0x8000
			0x00 0x05 0x28 0x2B 0x38 0x3B 0x6580 0x7180 0x8000
			0x00 0x06 0x24 0x27 0x38 0x3B 0x6A00 0x7100 0x8000
			0x00 0x07 0x20 0x23 0x38 0x3B 0x6E80 0x7080 0x8000
			0x00 0x08 0x1C 0x1F 0x38 0x3B 0x7380 0x7080 0x8000
			0x00 0x09 0x18 0x1B 0x38 0x3B 0x7880 0x7000 0x8000
			0x00 0x0A 0x14 0x17 0x38 0x3B 0x7E00 0x7000 0x8000
			0x00 0x0B 0x10 0x13 0x38 0x3B 0x8000 0x6D00 0x7D00
			0x00 0x0C 0x0C 0x0F 0x38 0x3B 0x8000 0x6780 0x7680
			0x00 0x0D 0x08 0x0B 0x38 0x3B 0x8000 0x6100 0x6F00
			0x00 0x0E 0x04 0x07 0x38 0x3B 0x8000 0x5980 0x6600
			0x00 0x0F 0x00 0x03 0x38 0x3B 0x8000 0x5100 0x5B80
			0x00 0x10 0x38 0x3B 0x34 0x37 0x5A80 0x7680 0x8000
			0x00 0x11 0x34 0x37 0x34 0x37 0x5E00 0x7600 0x8000
			0x00 0x12 0x30 0x33 0x34 0x37 0x6200 0x7580 0x8000
			0x00 0x13 0x2C 0x2F 0x34 0x37 0x6600 0x7500 0x8000
			0x00 0x14 0x28 0x2B 0x34 0x37 0x6A00 0x7480 0x8000
			0x00 0x15 0x24 0x27 0x34 0x37 0x6E80 0x7400 0x8000
			0x00 0x16 0x20 0x23 0x34 0x37 0x7300 0x7400 0x8000
			0x00 0x17 0x1C 0x1F 0x34 0x37 0x7800 0x7380 0x8000
			0x00 0x18 0x18 0x1B 0x34 0x37 0x7D00 0x7300 0x8000
			0x00 0x19 0x14 0x17 0x34 0x37 0x8000 0x7180 0x7E80
			0x00 0x1A 0x10 0x13 0x34 0x37 0x8000 0x6C00 0x7880
			0x00 0x1B 0x0C 0x0F 0x34 0x37 0x8000 0x6600 0x7200
			0x00 0x1C 0x08 0x0B 0x34 0x37 0x8000 0x5F80 0x6A00
			0x00 0x1D 0x04 0x07 0x34 0x37 0x8000 0x5780 0x6100
			0x00 0x1E 0x00 0x03 0x34 0x37 0x8000 0x4E00 0x5680
			0x00 0x1F 0x38 0x3B 0x30 0x33 0x5F00 0x7A00 0x8000
			0x00 0x20 0x34 0x37 0x30 0x33 0x6280 0x7980 0x8000
			0x00 0x21 0x30 0x33 0x30 0x33 0x6600 0x7900 0x8000
			0x00 0x22 0x2C 0x2F 0x30 0x33 0x6A00 0x7880 0x8000
			0x00 0x23 0x28 0x2B 0x30 0x33 0x6E80 0x7800 0x8000
			0x00 0x24 0x24 0x27 0x30 0x33 0x7280 0x7780 0x8000
			0x00 0x25 0x20 0x23 0x30 0x33 0x7700 0x7700 0x8000
			0x00 0x26 0x1C 0x1F 0x30 0x33 0x7C00 0x7680 0x8000
			0x00 0x27 0x18 0x1B 0x30 0x33 0x8000 0x7580 0x7F80
			0x00 0x28 0x14 0x17 0x30 0x33 0x8000 0x7100 0x7A80
			0x00 0x29 0x10 0x13 0x30 0x33 0x8000 0x6B00 0x7480
			0x00 0x2A 0x0C 0x0F 0x30 0x33 0x8000 0x6500 0x6E00
			0x00 0x2B 0x08 0x0B 0x30 0x33 0x8000 0x5E00 0x6600
			0x00 0x2C 0x04 0x07 0x30 0x33 0x8000 0x5580 0x5D00
			0x00 0x2D 0x00 0x03 0x30 0x33 0x8000 0x4B00 0x5200
			0x00 0x2E 0x38 0x3B 0x2C 0x2F 0x6300 0x7D80 0x8000
			0x00 0x2F 0x34 0x37 0x2C 0x2F 0x6680 0x7C80 0x8000
			0x00 0x30 0x30 0x33 0x2C 0x2F 0x6A00 0x7C00 0x8000
			0x00 0x31 0x2C 0x2F 0x2C 0x2F 0x6E00 0x7B80 0x8000
			0x00 0x32 0x28 0x2B 0x2C 0x2F 0x7280 0x7B00 0x8000
			0x00 0x33 0x24 0x27 0x2C 0x2F 0x7680 0x7A80 0x8000
			0x00 0x34 0x20 0x23 0x2C 0x2F 0x7B00 0x7A00 0x8000
			0x00 0x35 0x1C 0x1F 0x2C 0x2F 0x8000 0x7980 0x8000
			0x00 0x36 0x18 0x1B 0x2C 0x2F 0x8000 0x7580 0x7C00
			0x00 0x37 0x14 0x17 0x2C 0x2F 0x8000 0x7000 0x7680
			0x00 0x38 0x10 0x13 0x2C 0x2F 0x8000 0x6A80 0x7100
			0x00 0x39 0x0C 0x0F 0x2C 0x2F 0x8000 0x6400 0x6A00
			0x00 0x3A 0x08 0x0B 0x2C 0x2F 0x8000 0x5C00 0x6200
			0x00 0x3B 0x04 0x07 0x2C 0x2F 0x8000 0x5300 0x5880
			0x00 0x3C 0x00 0x03 0x2C 0x2F 0x8000 0x4880 0x4D80
			0x00 0x3D 0x38 0x3B 0x28 0x2B 0x6600 0x8000 0x8000
			0x00 0x3E 0x34 0x37 0x28 0x2B 0x6A00 0x8000 0x8000
			0x00 0x3F 0x30 0x33 0x28 0x2B 0x6E00 0x7F80 0x8000
			0x00 0x40 0x2C 0x2F 0x28 0x2B 0x7200 0x7F00 0x8000
			0x00 0x41 0x28 0x2B 0x28 0x2B 0x7600 0x7E00 0x8000
			0x00 0x42 0x24 0x27 0x28 0x2B 0x7A80 0x7D80 0x8000
			0x00 0x43 0x20 0x23 0x28 0x2B 0x7F00 0x7D00 0x8000
			0x00 0x44 0x1C 0x1F 0x28 0x2B 0x8000 0x7A00 0x7D80
			0x00 0x45 0x18 0x1B 0x28 0x2B 0x8000 0x7500 0x7880
			0x00 0x46 0x14 0x17 0x28 0x2B 0x8000 0x6F80 0x7380
			0x00 0x47 0x10 0x13 0x28 0x2B 0x8000 0x6980 0x6D80
			0x00 0x48 0x0C 0x0F 0x28 0x2B 0x8000 0x6280 0x6680
			0x00 0x49 0x08 0x0B 0x28 0x2B 0x8000 0x5A80 0x5E80
			0x00 0x4A 0x04 0x07 0x28 0x2B 0x8000 0x5100 0x5500
			0x00 0x4B 0x00 0x03 0x28 0x2B 0x8000 0x4580 0x4980
			0x00 0x4C 0x38 0x3B 0x24 0x27 0x6500 0x8000 0x7C00
			0x00 0x4D 0x34 0x37 0x24 0x27 0x6980 0x8000 0x7D00
			0x00 0x4E 0x30 0x33 0x24 0x27 0x6E80 0x8000 0x7D80
			0x00 0x4F 0x2C 0x2F 0x24 0x27 0x7300 0x8000 0x7E80
			0x00 0x50 0x28 0x2B 0x24 0x27 0x7800 0x8000 0x7F00
			0x00 0x51 0x24 0x27 0x24 0x27 0x7D80 0x8000 0x8000
			0x00 0x52 0x20 0x23 0x24 0x27 0x8000 0x7E80 0x7E80
			0x00 0x53 0x1C 0x1F 0x24 0x27 0x8000 0x7A00 0x7A00
			0x00 0x54 0x18 0x1B 0x24 0x27 0x8000 0x7500 0x7580
			0x00 0x55 0x14 0x17 0x24 0x27 0x8000 0x6F00 0x7000
			0x00 0x56 0x10 0x13 0x24 0x27 0x8000 0x6880 0x6A00
			0x00 0x57 0x0C 0x0F 0x24 0x27 0x8000 0x6180 0x6300
			0x00 0x58 0x08 0x0B 0x24 0x27 0x8000 0x5880 0x5B00
			0x00 0x59 0x04 0x07 0x24 0x27 0x8000 0x4E80 0x5180
			0x00 0x5A 0x00 0x03 0x24 0x27 0x8000 0x4280 0x4580
			0x00 0x5B 0x38 0x3B 0x20 0x23 0x6380 0x8000 0x7880
			0x00 0x5C 0x34 0x37 0x20 0x23 0x6880 0x8000 0x7980
			0x00 0x5D 0x30 0x33 0x20 0x23 0x6D80 0x8000 0x7A00
			0x00 0x5E 0x2C 0x2F 0x20 0x23 0x7280 0x8000 0x7B00
			0x00 0x5F 0x28 0x2B 0x20 0x23 0x7780 0x8000 0x7C00
			0x00 0x60 0x24 0x27 0x20 0x23 0x7D00 0x8000 0x7C80
			0x00 0x61 0x20 0x23 0x20 0x23 0x8000 0x7E80 0x7B80
			0x00 0x62 0x1C 0x1F 0x20 0x23 0x8000 0x7A00 0x7700
			0x00 0x63 0x18 0x1B 0x20 0x23 0x8000 0x7480 0x7280
			0x00 0x64 0x14 0x17 0x20 0x23 0x8000 0x6E80 0x6D00
			0x00 0x65 0x10 0x13 0x20 0x23 0x8000 0x6800 0x6700
			0x00 0x66 0x0C 0x0F 0x20 0x23 0x8000 0x6000 0x6000
			0x00 0x67 0x08 0x0B 0x20 0x23 0x8000 0x5700 0x5800
			0x00 0x68 0x04 0x07 0x20 0x23 0x8000 0x4C00 0x4E00
			0x00 0x69 0x00 0x03 0x20 0x23 0x8000 0x3F00 0x4200
			0x00 0x6A 0x38 0x3B 0x1C 0x1F 0x6280 0x8000 0x7500
			0x00 0x6B 0x34 0x37 0x1C 0x1F 0x6780 0x8000 0x7600
			0x00 0x6C 0x30 0x33 0x1C 0x1F 0x6C80 0x8000 0x7700
			0x00 0x6D 0x2C 0x2F 0x1C 0x1F 0x7200 0x8000 0x7800
			0x00 0x6E 0x28 0x2B 0x1C 0x1F 0x7700 0x8000 0x7880
			0x00 0x6F 0x24 0x27 0x1C 0x1F 0x7C80 0x8000 0x7980
			0x00 0x70 0x20 0x23 0x1C 0x1F 0x8000 0x7F00 0x7900
			0x00 0x71 0x18 0x1B 0x1C 0x1F 0x8000 0x7480 0x6F80
			0x00 0x72 0x14 0x17 0x1C 0x1F 0x8000 0x6E00 0x6A80
			0x00 0x73 0x10 0x13 0x1C 0x1F 0x8000 0x6700 0x6400
			0x00 0x74 0x0C 0x0F 0x1C 0x1F 0x8000 0x5F00 0x5D00
			0x00 0x75 0x08 0x0B 0x1C 0x1F 0x8000 0x5500 0x5500
			0x00 0x76 0x04 0x07 0x1C 0x1F 0x8000 0x4A00 0x4B00
			0x00 0x77 0x00 0x03 0x1C 0x1F 0x8000 0x3C00 0x3F00
			0x00 0x78 0x38 0x3B 0x18 0x1B 0x6100 0x8000 0x7200
			0x00 0x79 0x34 0x37 0x18 0x1B 0x6600 0x8000 0x7300
			0x00 0x7A 0x30 0x33 0x18 0x1B 0x6B80 0x8000 0x7400
			0x00 0x7B 0x2C 0x2F 0x18 0x1B 0x7100 0x8000 0x7500
			0x00 0x7C 0x28 0x2B 0x18 0x1B 0x7680 0x8000 0x7600
			0x00 0x7D 0x24 0x27 0x18 0x1B 0x7C00 0x8000 0x7680
			0x00 0x7E 0x20 0x23 0x18 0x1B 0x8000 0x7F00 0x7680
			0x00 0x7F 0x1C 0x1F 0x18 0x1B 0x8000 0x7A00 0x7200
			0x00 0x80 0x18 0x1B 0x18 0x1B 0x8000 0x7400 0x6D00
			0x00 0x81 0x14 0x17 0x18 0x1B 0x8000 0x6D80 0x6800
			0x00 0x82 0x10 0x13 0x18 0x1B 0x8000 0x6600 0x6180
			0x00 0x83 0x0C 0x0F 0x18 0x1B 0x8000 0x5D80 0x5A80
			0x00 0x84 0x08 0x0B 0x18 0x1B 0x8000 0x5380 0x5200
			0x00 0x85 0x04 0x07 0x18 0x1B 0x8000 0x4780 0x4800
			0x00 0x86 0x00 0x03 0x18 0x1B 0x8000 0x3880 0x3C00
			0x00 0x87 0x38 0x3B 0x14 0x17 0x5F80 0x8000 0x6F00
			0x00 0x88 0x34 0x37 0x14 0x17 0x6500 0x8000 0x7000
			0x00 0x89 0x30 0x33 0x14 0x17 0x6A80 0x8000 0x7100
			0x00 0x8A 0x2C 0x2F 0x14 0x17 0x7000 0x8000 0x7200
			0x00 0x8B 0x28 0x2B 0x14 0x17 0x7600 0x8000 0x7300
			0x00 0x8C 0x24 0x27 0x14 0x17 0x7B80 0x8000 0x7400
			0x00 0x8D 0x20 0x23 0x14 0x17 0x8000 0x7F00 0x7400
			0x00 0x8E 0x1C 0x1F 0x14 0x17 0x8000 0x7A00 0x6F80
			0x00 0x8F 0x18 0x1B 0x14 0x17 0x8000 0x7400 0x6B00
			0x00 0x90 0x14 0x17 0x14 0x17 0x8000 0x6D00 0x6580
			0x00 0x91 0x10 0x13 0x14 0x17 0x8000 0x6580 0x5F80
			0x00 0x92 0x0C 0x0F 0x14 0x17 0x8000 0x5C80 0x5800
			0x00 0x93 0x08 0x0B 0x14 0x17 0x8000 0x5180 0x4F80
			0x00 0x94 0x04 0x07 0x14 0x17 0x8000 0x4500 0x4580
			0x00 0x95 0x00 0x03 0x14 0x17 0x8000 0x3580 0x3900
			0x00 0x96 0x38 0x3B 0x10 0x13 0x5E00 0x8000 0x6C00
			0x00 0x97 0x34 0x37 0x10 0x13 0x6400 0x8000 0x6D80
			0x00 0x98 0x30 0x33 0x10 0x13 0x6980 0x8000 0x6E80
			0x00 0x99 0x2C 0x2F 0x10 0x13 0x6F80 0x8000 0x6F80
			0x00 0x9A 0x28 0x2B 0x10 0x13 0x7500 0x8000 0x7080
			0x00 0x9B 0x24 0x27 0x10 0x13 0x7B00 0x8000 0x7180
			0x00 0x9C 0x20 0x23 0x10 0x13 0x8000 0x7F80 0x7200
			0x00 0x9D 0x1C 0x1F 0x10 0x13 0x8000 0x7A00 0x6D80
			0x00 0x9E 0x18 0x1B 0x10 0x13 0x8000 0x7380 0x6900
			0x00 0x9F 0x14 0x17 0x10 0x13 0x8000 0x6C80 0x6380
			0x00 0xA0 0x10 0x13 0x10 0x13 0x8000 0x6480 0x5D00
			0x00 0xA1 0x0C 0x0F 0x10 0x13 0x8000 0x5B00 0x5600
			0x00 0xA2 0x08 0x0B 0x10 0x13 0x8000 0x5000 0x4D80
			0x00 0xA3 0x04 0x07 0x10 0x13 0x8000 0x4280 0x4300
			0x00 0xA4 0x00 0x03 0x10 0x13 0x8000 0x3200 0x3680
			0x00 0xA5 0x38 0x3B 0x0C 0x0F 0x5C80 0x8000 0x6980
			0x00 0xA6 0x34 0x37 0x0C 0x0F 0x6280 0x8000 0x6B00
			0x00 0xA7 0x30 0x33 0x0C 0x0F 0x6880 0x8000 0x6C00
			0x00 0xA8 0x2C 0x2F 0x0C 0x0F 0x6E80 0x8000 0x6D00
			0x00 0xA9 0x28 0x2B 0x0C 0x0F 0x7480 0x8000 0x6E80
			0x00 0xAA 0x24 0x27 0x0C 0x0F 0x7A80 0x8000 0x6F80
			0x00 0xAB 0x20 0x23 0x0C 0x0F 0x8000 0x7F80 0x7000
			0x00 0xAC 0x1C 0x1F 0x0C 0x0F 0x8000 0x7A00 0x6B80
			0x00 0xAD 0x18 0x1B 0x0C 0x0F 0x8000 0x7380 0x6700
			0x00 0xAE 0x14 0x17 0x0C 0x0F 0x8000 0x6C00 0x6180
			0x00 0xAF 0x10 0x13 0x0C 0x0F 0x8000 0x6380 0x5B00
			0x00 0xB0 0x0C 0x0F 0x0C 0x0F 0x8000 0x5980 0x5400
			0x00 0xB1 0x08 0x0B 0x0C 0x0F 0x8000 0x4E00 0x4B80
			0x00 0xB2 0x04 0x07 0x0C 0x0F 0x8000 0x3F80 0x4100
			0x00 0xB3 0x00 0x03 0x0C 0x0F 0x8000 0x2E80 0x3400
			0x00 0xB4 0x38 0x3B 0x08 0x0B 0x5B00 0x8000 0x6700
			0x00 0xB5 0x34 0x37 0x08 0x0B 0x6100 0x8000 0x6880
			0x00 0xB6 0x30 0x33 0x08 0x0B 0x6780 0x8000 0x6980
			0x00 0xB7 0x2C 0x2F 0x08 0x0B 0x6D80 0x8000 0x6B00
			0x00 0xB8 0x28 0x2B 0x08 0x0B 0x7400 0x8000 0x6C00
			0x00 0xB9 0x24 0x27 0x08 0x0B 0x7A00 0x8000 0x6D00
			0x00 0xBA 0x20 0x23 0x08 0x0B 0x8000 0x8000 0x6E00
			0x00 0xBB 0x1C 0x1F 0x08 0x0B 0x8000 0x7A00 0x6A00
			0x00 0xBC 0x18 0x1B 0x08 0x0B 0x8000 0x7380 0x6500
			0x00 0xBD 0x14 0x17 0x08 0x0B 0x8000 0x6B80 0x5F80
			0x00 0xBE 0x10 0x13 0x08 0x0B 0x8000 0x6280 0x5980
			0x00 0xBF 0x0C 0x0F 0x08 0x0B 0x8000 0x5880 0x5200
			0x00 0xC0 0x08 0x0B 0x08 0x0B 0x8000 0x4C00 0x4980
			0x00 0xC1 0x04 0x07 0x08 0x0B 0x8000 0x3D00 0x3F00
			0x00 0xC2 0x00 0x03 0x08 0x0B 0x8000 0x2A80 0x3200
			0x00 0xC3 0x38 0x3B 0x04 0x07 0x5980 0x8000 0x6480
			0x00 0xC4 0x34 0x37 0x04 0x07 0x5F80 0x8000 0x6600
			0x00 0xC5 0x30 0x33 0x04 0x07 0x6600 0x8000 0x6780
			0x00 0xC6 0x2C 0x2F 0x04 0x07 0x6C80 0x8000 0x6900
			0x00 0xC7 0x28 0x2B 0x04 0x07 0x7300 0x8000 0x6A00
			0x00 0xC8 0x24 0x27 0x04 0x07 0x7980 0x8000 0x6B00
			0x00 0xC9 0x20 0x23 0x04 0x07 0x8000 0x8000 0x6C80
			0x00 0xCA 0x1C 0x1F 0x04 0x07 0x8000 0x7A00 0x6800
			0x00 0xCB 0x18 0x1B 0x04 0x07 0x8000 0x7300 0x6380
			0x00 0xCC 0x14 0x17 0x04 0x07 0x8000 0x6B00 0x5E00
			0x00 0xCD 0x10 0x13 0x04 0x07 0x8000 0x6200 0x5780
			0x00 0xCE 0x0C 0x0F 0x04 0x07 0x8000 0x5700 0x5080
			0x00 0xCF 0x08 0x0B 0x04 0x07 0x8000 0x4A00 0x4780
			0x00 0xD0 0x04 0x07 0x04 0x07 0x8000 0x3A80 0x3D00
			0x00 0xD1 0x00 0x03 0x04 0x07 0x8000 0x2700 0x2F80
			0x00 0xD2 0x38 0x3B 0x00 0x03 0x5780 0x8000 0x6280
			0x00 0xD3 0x34 0x37 0x00 0x03 0x5E00 0x8000 0x6400
			0x00 0xD4 0x30 0x33 0x00 0x03 0x6500 0x8000 0x6580
			0x00 0xD5 0x2C 0x2F 0x00 0x03 0x6B80 0x8000 0x6700
			0x00 0xD6 0x28 0x2B 0x00 0x03 0x7200 0x8000 0x6800
			0x00 0xD7 0x24 0x27 0x00 0x03 0x7900 0x8000 0x6980
			0x00 0xD8 0x20 0x23 0x00 0x03 0x8000 0x8000 0x6A80
			0x00 0xD9 0x1C 0x1F 0x00 0x03 0x8000 0x7A00 0x6680
			0x00 0xDA 0x18 0x1B 0x00 0x03 0x8000 0x7300 0x6200
			0x00 0xDB 0x14 0x17 0x00 0x03 0x8000 0x6A80 0x5C80
			0x00 0xDC 0x10 0x13 0x00 0x03 0x8000 0x6100 0x5600
			0x00 0xDD 0x0C 0x0F 0x00 0x03 0x8000 0x5580 0x4F00
			0x00 0xDE 0x08 0x0B 0x00 0x03 0x8000 0x4800 0x4600
			0x00 0xDF 0x04 0x07 0x00 0x03 0x8000 0x3780 0x3B80
			0x00 0xE0 0x00 0x03 0x00 0x03 0x8000 0x2300 0x2E00
			0xFF 0x00 0x00 0x3B 0x00 0x3B 0x8000 0x8000 0x8000>;
	};

	dsi_default_gpio_0: somc,default_cmd_panel_0 {
		qcom,mdss-dsi-panel-name = "default";
		qcom,mdss-dsi-panel-controller = <&mdss_dsi0>;
		qcom,mdss-dsi-panel-destination = "display_1";
		qcom,mdss-dsi-panel-type = "dsi_cmd_mode";
		qcom,mdss-dsi-panel-width = <1080>;
		qcom,mdss-dsi-panel-height = <1920>;
		qcom,mdss-dsi-bpp = <24>;
		qcom,mdss-dsi-h-back-porch = <8>;
		qcom,mdss-dsi-h-pulse-width = <8>;
		qcom,mdss-dsi-h-front-porch = <56>;
		qcom,mdss-dsi-v-back-porch = <8>;
		qcom,mdss-dsi-v-pulse-width = <2>;
		qcom,mdss-dsi-v-front-porch = <233>;
		qcom,mdss-pan-physical-width-dimension = <64>;
		qcom,mdss-pan-physical-height-dimension = <114>;
		qcom,mdss-dsi-panel-framerate = <60>;
		qcom,mdss-dsi-virtual-channel-id = <0>;
		qcom,mdss-dsi-stream = <0>;
		qcom,mdss-dsi-h-sync-skew = <0>;
		qcom,mdss-dsi-h-left-border = <0>;
		qcom,mdss-dsi-h-right-border = <0>;
		qcom,mdss-dsi-v-top-border = <0>;
		qcom,mdss-dsi-v-bottom-border = <0>;
		qcom,mdss-dsi-underflow-color = <0x0>;
		qcom,mdss-dsi-border-color = <0>;
		qcom,mdss-dsi-h-sync-pulse = <1>;
		qcom,mdss-dsi-traffic-mode = "non_burst_sync_event";
		qcom,mdss-dsi-bllp-eof-power-mode;
		qcom,mdss-dsi-bllp-power-mode;
		qcom,mdss-dsi-dma-trigger = "trigger_sw";
		qcom,mdss-dsi-mdp-trigger = "none";
		somc,mdss-dsi-init-command = [15 01 00 00 00 00 02 FF E0
				15 01 00 00 00 00 02 FB 01
				15 01 00 00 00 00 02 B5 86
				15 01 00 00 00 00 02 B6 77
				15 01 00 00 00 00 02 B8 AD
				15 01 00 00 00 00 02 FF 20
				15 01 00 00 00 00 02 FB 01
				15 01 00 00 00 00 02 2D 14
				15 01 00 00 00 00 02 FF 24
				15 01 00 00 00 00 02 FB 01
				15 01 00 00 00 00 02 C6 00
				15 01 00 00 00 00 02 92 8B
				15 01 00 00 00 00 02 C5 32
				15 01 00 00 00 00 02 FF 10
				15 01 00 00 00 00 02 35 00
				39 01 00 00 00 00 03 44 03 00
				39 01 00 00 00 00 04 3B 03 30 06
				15 01 00 00 01 00 02 BB 10
				05 01 00 00 1E 00 01 11];
		qcom,mdss-dsi-on-command = [05 01 00 00 28 00 01 29];
		qcom,mdss-dsi-off-command = [05 01 00 00 00 00 01 28
				05 01 00 00 64 00 01 10];
		qcom,mdss-dsi-on-command-state = "dsi_lp_mode";
		qcom,mdss-dsi-off-command-state = "dsi_hs_mode";
		qcom,mdss-dsi-te-pin-select = <1>;
		qcom,mdss-dsi-wr-mem-start = <0x2c>;
		qcom,mdss-dsi-wr-mem-continue = <0x3c>;
		qcom,mdss-dsi-te-dcs-command = <1>;
		qcom,mdss-dsi-te-check-enable;
		qcom,mdss-dsi-te-using-te-pin;
		qcom,mdss-dsi-lane-0-state;
		qcom,mdss-dsi-lane-1-state;
		qcom,mdss-dsi-lane-2-state;
		qcom,mdss-dsi-lane-3-state;
		qcom,mdss-dsi-panel-timings = [E6 38 26 00 68 66 32 3C 2C 03 04 00];
		qcom,mdss-dsi-t-clk-post = <0x21>;
		qcom,mdss-dsi-t-clk-pre = <0x2B>;
		qcom,mdss-dsi-tx-eot-append;
		qcom,mdss-dsi-lp11-init;
		qcom,mdss-dsi-bl-min-level = <1>;
		qcom,mdss-dsi-bl-max-level = <4095>;
		qcom,mdss-brightness-max-level = <4095>;
		qcom,mdss-dsi-bl-pmic-control-type = "bl_ctrl_wled";
		qcom,qpnp-lab-limit-maximum-current = <200>;
		qcom,qpnp-ibb-limit-maximum-current = <800>;

		somc,mdss-dsi-disp-on-in-hs = <0>;
		somc,mdss-dsi-wait-time-before-on-cmd = <0>;
		somc,platform-regulator-settings = [03 03 03 00 20 00 01];
		somc,mdss-dsi-lane-config = [02 00 EF 00 20 00 00 01 FF
				02 00 EF 00 40 00 00 01 FF
				02 00 EF 40 20 00 00 01 FF
				02 00 EF 40 00 00 00 01 FF
				00 00 45 80 00 00 00 01 97];
		somc,disp-en-on-pre = <1>;
		somc,pw-on-rst-seq = <0 20>, <1 10>;
		somc,disp-en-off-post = <70>;
		somc,pw-off-rst-seq = <0 0>;
		somc,pw-down-period = <100>;
		somc,lab-output-voltage = <5400000>;
		somc,ibb-output-voltage = <5400000>;
		somc,lcd-id = <0>;
		somc,lcd-id-adc = <0 0x7fffffff>;
		somc,mdss-dsi-master;
	};

	dsi_default_gpio_1: somc,default_cmd_panel_1 {
		qcom,mdss-dsi-panel-name = "default";
		qcom,mdss-dsi-panel-controller = <&mdss_dsi0>;
		qcom,mdss-dsi-panel-destination = "display_1";
		qcom,mdss-dsi-panel-type = "dsi_cmd_mode";
		qcom,mdss-dsi-panel-width = <1080>;
		qcom,mdss-dsi-panel-height = <1920>;
		qcom,mdss-dsi-bpp = <24>;
		qcom,mdss-dsi-h-back-porch = <8>;
		qcom,mdss-dsi-h-pulse-width = <8>;
		qcom,mdss-dsi-h-front-porch = <56>;
		qcom,mdss-dsi-v-back-porch = <8>;
		qcom,mdss-dsi-v-pulse-width = <2>;
		qcom,mdss-dsi-v-front-porch = <233>;
		qcom,mdss-pan-physical-width-dimension = <64>;
		qcom,mdss-pan-physical-height-dimension = <114>;
		qcom,mdss-dsi-panel-framerate = <60>;
		qcom,mdss-dsi-virtual-channel-id = <0>;
		qcom,mdss-dsi-stream = <0>;
		qcom,mdss-dsi-h-sync-skew = <0>;
		qcom,mdss-dsi-h-left-border = <0>;
		qcom,mdss-dsi-h-right-border = <0>;
		qcom,mdss-dsi-v-top-border = <0>;
		qcom,mdss-dsi-v-bottom-border = <0>;
		qcom,mdss-dsi-underflow-color = <0x0>;
		qcom,mdss-dsi-border-color = <0>;
		qcom,mdss-dsi-h-sync-pulse = <1>;
		qcom,mdss-dsi-traffic-mode = "non_burst_sync_event";
		qcom,mdss-dsi-bllp-eof-power-mode;
		qcom,mdss-dsi-bllp-power-mode;
		qcom,mdss-dsi-dma-trigger = "trigger_sw";
		qcom,mdss-dsi-mdp-trigger = "none";
		somc,mdss-dsi-init-command = [15 01 00 00 00 00 02 FF E0
				15 01 00 00 00 00 02 FB 01
				15 01 00 00 00 00 02 B5 86
				15 01 00 00 00 00 02 B6 77
				15 01 00 00 00 00 02 B8 AD
				15 01 00 00 00 00 02 FF 20
				15 01 00 00 00 00 02 FB 01
				15 01 00 00 00 00 02 2D 14
				15 01 00 00 00 00 02 FF 24
				15 01 00 00 00 00 02 FB 01
				15 01 00 00 00 00 02 C6 00
				15 01 00 00 00 00 02 92 8B
				15 01 00 00 00 00 02 C5 32
				15 01 00 00 00 00 02 FF 10
				15 01 00 00 00 00 02 35 00
				39 01 00 00 00 00 03 44 03 00
				39 01 00 00 00 00 04 3B 03 30 06
				15 01 00 00 01 00 02 BB 10
				05 01 00 00 1E 00 01 11];
		qcom,mdss-dsi-on-command = [05 01 00 00 28 00 01 29];
		qcom,mdss-dsi-off-command = [05 01 00 00 00 00 01 28
				05 01 00 00 64 00 01 10];
		qcom,mdss-dsi-on-command-state = "dsi_lp_mode";
		qcom,mdss-dsi-off-command-state = "dsi_hs_mode";
		qcom,mdss-dsi-te-pin-select = <1>;
		qcom,mdss-dsi-wr-mem-start = <0x2c>;
		qcom,mdss-dsi-wr-mem-continue = <0x3c>;
		qcom,mdss-dsi-te-dcs-command = <1>;
		qcom,mdss-dsi-te-check-enable;
		qcom,mdss-dsi-te-using-te-pin;
		qcom,mdss-dsi-lane-0-state;
		qcom,mdss-dsi-lane-1-state;
		qcom,mdss-dsi-lane-2-state;
		qcom,mdss-dsi-lane-3-state;
		qcom,mdss-dsi-panel-timings = [E6 38 26 00 68 66 32 3C 2C 03 04 00];
		qcom,mdss-dsi-t-clk-post = <0x21>;
		qcom,mdss-dsi-t-clk-pre = <0x2B>;
		qcom,mdss-dsi-tx-eot-append;
		qcom,mdss-dsi-lp11-init;
		qcom,mdss-dsi-bl-min-level = <1>;
		qcom,mdss-dsi-bl-max-level = <4095>;
		qcom,mdss-brightness-max-level = <4095>;
		qcom,mdss-dsi-bl-pmic-control-type = "bl_ctrl_wled";
		qcom,qpnp-lab-limit-maximum-current = <200>;
		qcom,qpnp-ibb-limit-maximum-current = <800>;

		somc,mdss-dsi-disp-on-in-hs = <0>;
		somc,mdss-dsi-wait-time-before-on-cmd = <0>;
		somc,platform-regulator-settings = [03 03 03 00 20 00 01];
		somc,mdss-dsi-lane-config = [02 00 EF 00 20 00 00 01 FF
				02 00 EF 00 40 00 00 01 FF
				02 00 EF 40 20 00 00 01 FF
				02 00 EF 40 00 00 00 01 FF
				00 00 45 80 00 00 00 01 97];
		somc,disp-en-on-pre = <1>;
		somc,pw-on-rst-seq = <0 20>, <1 10>;
		somc,disp-en-off-post = <70>;
		somc,pw-off-rst-seq = <0 0>;
		somc,pw-down-period = <100>;
		somc,lab-output-voltage = <5400000>;
		somc,ibb-output-voltage = <5400000>;
		somc,lcd-id = <1>;
		somc,lcd-id-adc = <0 0x7fffffff>;
		somc,mdss-dsi-master;
	};
};
